AUTOSAR XML (schema 00047)
standard types defined: boolean, uint16, uint32, uint8
package /Application/AdaptiveApplicationSwComponentTypes
  adaptive application sw component type DiagnosticManagerDeamon
    require port DiagComApiDeamonPort: required-interface=DiagComApi
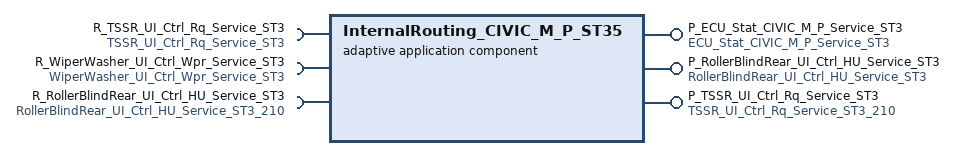
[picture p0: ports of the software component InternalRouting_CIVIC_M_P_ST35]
  adaptive application sw component type InternalRouting_CIVIC_M_P_ST35
    provide port P_ECU_Stat_CIVIC_M_P_Service_ST3: provided-interface=ECU_Stat_CIVIC_M_P_Service_ST3
    require port R_TSSR_UI_Ctrl_Rq_Service_ST3: required-interface=TSSR_UI_Ctrl_Rq_Service_ST3
    require port R_WiperWasher_UI_Ctrl_Wpr_Service_ST3: required-interface=WiperWasher_UI_Ctrl_Wpr_Service_ST3
    provide port P_RollerBlindRear_UI_Ctrl_HU_Service_ST3: provided-interface=RollerBlindRear_UI_Ctrl_HU_Service_ST3
    require port R_RollerBlindRear_UI_Ctrl_HU_Service_ST3: required-interface=RollerBlindRear_UI_Ctrl_HU_Service_ST3_210
    provide port P_TSSR_UI_Ctrl_Rq_Service_ST3: provided-interface=TSSR_UI_Ctrl_Rq_Service_ST3_210
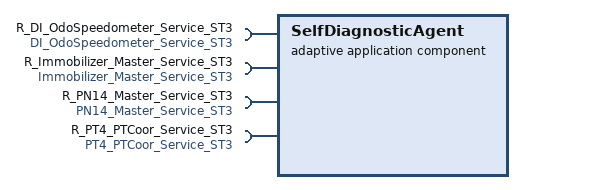
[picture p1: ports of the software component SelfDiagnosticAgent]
  adaptive application sw component type SelfDiagnosticAgent
    4 x require port:
      R_DI_OdoSpeedometer_Service_ST3: required-interface=DI_OdoSpeedometer_Service_ST3
      R_Immobilizer_Master_Service_ST3: required-interface=Immobilizer_Master_Service_ST3
      R_PN14_Master_Service_ST3: required-interface=PN14_Master_Service_ST3
      R_PT4_PTCoor_Service_ST3: required-interface=PT4_PTCoor_Service_ST3
  adaptive application sw component type SsaDiag_swc
    provide port amsr_DiagComApi: provided-interface=DiagComApi
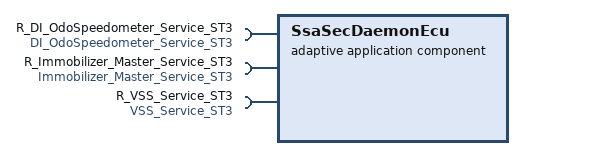
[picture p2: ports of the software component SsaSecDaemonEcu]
  adaptive application sw component type SsaSecDaemonEcu
    require port R_DI_OdoSpeedometer_Service_ST3: required-interface=DI_OdoSpeedometer_Service_ST3
    require port R_Immobilizer_Master_Service_ST3: required-interface=Immobilizer_Master_Service_ST3
    require port R_VSS_Service_ST3: required-interface=VSS_Service_ST3
package /Application/Executables
  5 x executable, all with category=APPLICATION_LEVEL, build-type=BUILD-TYPE-DEBUG, version=1.00.00.0000:
    DiagnosticManagerDeamon_Executable
      root sw component prototype DiagnosticManagerDeamon_ExecutableRootSwc: application-type=DiagnosticManagerDeamon
    InternalRouting_CIVIC_M_P_ST35_Executable
      root sw component prototype InternalRouting_CIVIC_M_P_ST35_ExecutableRootSwc: application-type=InternalRouting_CIVIC_M_P_ST35
    SelfDiagnosticAgent_Executable
      root sw component prototype SelfDiagnosticAgent_ExecutableRootSwc: application-type=SelfDiagnosticAgent
    amsr_ssadiag
      root sw component prototype amsr_ssadiagRootSwc: application-type=SsaDiag_swc
    amsr_ssasecd
      root sw component prototype amsr_ssasecdRootSwc: application-type=SsaSecDaemonEcu
package /ApplicationDeployment/ProcessDesigns
  5 x process design:
    DiagnosticManagerDeamonDesign: executable=DiagnosticManagerDeamon_Executable
    InternalRouting_CIVIC_M_P_ST35_ProcessDesign: executable=InternalRouting_CIVIC_M_P_ST35_Executable
    SelfDiagnosticAgent_ProcessDesign: executable=SelfDiagnosticAgent_Executable
    amsr_ssadiagdDesign: executable=amsr_ssadiag
    amsr_ssasecdDesign: executable=amsr_ssasecd
package /ApplicationDeployment/Processes
  5 x process:
    DiagnosticManagerDeamon: design=DiagnosticManagerDeamonDesign, executable=DiagnosticManagerDeamon_Executable, state-dependent-startup-config{function-group-state=MachineState.Running, startup-config=STARTUP_CONFIG_DEFAULT}
    InternalRouting_CIVIC_M_P_ST35_Process: design=InternalRouting_CIVIC_M_P_ST35_ProcessDesign, executable=InternalRouting_CIVIC_M_P_ST35_Executable, state-dependent-startup-config{function-group-state=MachineState.Running, startup-config=STARTUP_CONFIG_DEFAULT}
      process state machine ProcessStateMachine_InternalRouting_CIVIC_M_P_ST35: type=MachineStates
    SelfDiagnosticAgent_Process: design=SelfDiagnosticAgent_ProcessDesign, executable=SelfDiagnosticAgent_Executable, state-dependent-startup-config{function-group-state=MachineState.Running, startup-config=STARTUP_CONFIG_DEFAULT}
      process state machine ProcessStateMachine_SelfDiagnosticAgent: type=MachineStates
    amsr_ssadiagd: design=amsr_ssadiagdDesign, executable=amsr_ssadiag, state-dependent-startup-config{function-group-state=MachineState.Running, startup-config=SsaDiag_startup_config}
      process state machine ProcessStateMachine_amsr_ssadiagd: type=MachineStates
    amsr_ssasecd: design=amsr_ssasecdDesign, executable=amsr_ssasecd, state-dependent-startup-config{function-group-state=MachineState.Running, startup-config=startup_config}
      process state machine ProcessStateMachine_amsr_ssasecd: type=MachineStates
package /Communication/PDUs
  pdu DI_OdoSpeedometer_ST3: length=8, minimum-delay=0.1, unused-bit-pattern=255  # DriverInformation Odometer and speedometer
    signal Odo_ST3: start 24, 24 bit, little-endian, data-type-policy=OVERRIDE, i-signal-type=PRIMITIVE, base-type=uint32, invalid-value=16777215, compu {phys=raw*0.1 for raw 0..9999999, 16777214=I_C24_KM_0_999999K9_0K1_INVLD_SNA_INVLD (INVLD) (Invalid), 16777215=I_C24_KM_0_999999K9_0K1_INVLD_SNA_SNA (SNA) (SNA value from data type); unit km}, range phys 0..1677721.5, raw 0..16777215 "24_km_0-999999,9_0,1_Invld_SNA", to CIVIC_M_P_STAR_35_ExecutionContext  # Odometer (for everyone)
    mapping CRC_DI_Odo_Pr5_ST3: transfer-property=PENDING
    mapping DI_Odo_Pr5_ST3_e68xmtlkywxgxsdwekdjjhw3t: i-signal-group=DI_Odo_Pr5_ST3_e68xmtlkywxgxsdwekdjjhw3t, transfer-property=TRIGGERED-ON-CHANGE
    mapping SQC_DI_Odo_Pr5_ST3: transfer-property=PENDING
    mapping VehSpd_Disp_ST3: transfer-property=PENDING
  pdu ECU_Stat_CIVIC_M_P_ST3: length=8, unused-bit-pattern=0  # ECU state
    signal ECU_Id_CIVIC_M_P_ST3: start 0, 12 bit, little-endian, data-type-policy=OVERRIDE, i-signal-type=PRIMITIVE, base-type=uint16, invalid-value=4095, compu {phys=raw for raw 0..4094, 4095=I_C12_0_4094_1_SNA_SNA (SNA) (SNA value from data type)}, range phys 0..4095, raw 0..4095 "12_0-4094_1_SNA", transfer-property=PENDING  # ECU identifier
    signal WakeupRsn_CIVIC_M_P_ST3: start 20, 10 bit, little-endian, data-type-policy=OVERRIDE, i-signal-type=PRIMITIVE, base-type=uint16, invalid-value=1023, compu {0=I_C10_WAKEUPRSN_ST3_NETWORK (NETWORK) (Wakeup by network), 1=I_C10_WAKEUPRSN_ST3_NW_MAIN (NW_MAIN) (Wakeup by MAIN Ethernet), 11=I_C10_WAKEUPRSN_ST3_NW_HEADUNIT1 (NW_HEADUNIT1) (Wakeup by HEADUNIT1 CAN), 12=I_C10_WAKEUPRSN_ST3_NW_HEADUNIT2 (NW_HEADUNIT2) (Wakeup by HEADUNIT2 CAN), 13=I_C10_WAKEUPRSN_ST3_NW_PERIPHERY (NW_PERIPHERY) (Wakeup by PERIPHERY CAN), 14=I_C10_WAKEUPRSN_ST3_NW_BODY1 (NW_BODY1) (Wakeup by BODY1 CAN), 15=I_C10_WAKEUPRSN_ST3_NW_CHASSIS (NW_CHASSIS) (Wakeup by CHASSIS FlexRay), 16=I_C10_WAKEUPRSN_ST3_NW_RADAR_R (NW_RADAR_R) (Wakeup by RADAR_R CAN), 17=I_C10_WAKEUPRSN_ST3_NW_RADAR_F (NW_RADAR_F) (Wakeup by RADAR_F CAN), 18=I_C10_WAKEUPRSN_ST3_NW_OBD_PTI (NW_OBD_PTI) (Wakeup by OBD_PTI CAN), 19=I_C10_WAKEUPRSN_ST3_NW_STEERING_WHEEL (NW_STEERING_WHEEL) (Wakeup by STEERING_WHEEL CAN), 20=I_C10_WAKEUPRSN_ST3_NW_CPC (NW_CPC) (Wakeup by CPC CAN), 21=I_C10_WAKEUPRSN_ST3_NW_ECM (NW_ECM) (Wakeup by ECM CAN), 22=I_C10_WAKEUPRSN_ST3_NW_ENERGY (NW_ENERGY) (Wakeup by ENERGY CAN), 23=I_C10_WAKEUPRSN_ST3_NW_INV (NW_INV) (Wakeup by INV CAN), 24=I_C10_WAKEUPRSN_ST3_NW_TCM (NW_TCM) (Wakeup by TCM CAN), 25=I_C10_WAKEUPRSN_ST3_NW_AEPU (NW_AEPU) (Wakeup by AEPU CAN), 26=I_C10_WAKEUPRSN_ST3_NW_BODY2 (NW_BODY2) (Wakeup by BODY2 CAN), 27=I_C10_WAKEUPRSN_ST3_NW_BODY3 (NW_BODY3) (Wakeup by BODY3 CAN), 28=I_C10_WAKEUPRSN_ST3_NW_CAL_COC (NW_CAL_COC) (Wakeup by CAL_COC CAN), 29=I_C10_WAKEUPRSN_ST3_NW_CAL_DL (NW_CAL_DL) (Wakeup by CAL_DL CAN), 30=I_C10_WAKEUPRSN_ST3_NW_CAL_DR (NW_CAL_DR) (Wakeup by CAL_DR CAN), 31=I_C10_WAKEUPRSN_ST3_NW_ECM_PERIPHERY1 (NW_ECM_PERIPHERY1) (Wakeup by ECM_PERIPHERY1 CAN), 32=I_C10_WAKEUPRSN_ST3_NW_ECM_PERIPHERY2 (NW_ECM_PERIPHERY2) (Wakeup by ECM_PERIPHERY2 CAN), 33=I_C10_WAKEUPRSN_ST3_NW_ENGINE_PT3 (NW_ENGINE_PT3) (Wakeup by ENGINE_PT3 CAN), 34=I_C10_WAKEUPRSN_ST3_NW_HAD_BACKUP (NW_HAD_BACKUP) (Wakeup by HAD_BACKUP CAN), 35=I_C10_WAKEUPRSN_ST3_NW_HYBRID_PT3 (NW_HYBRID_PT3) (Wakeup by HYBRID_PT3 CAN), 36=I_C10_WAKEUPRSN_ST3_NW_LSM_F (NW_LSM_F) (Wakeup by LSM_F CAN), 37=I_C10_WAKEUPRSN_ST3_NW_POWERTRAIN_PT3 (NW_POWERTRAIN_PT3) (Wakeup by POWERTRAIN_PT3 CAN), 38=I_C10_WAKEUPRSN_ST3_NW_PT_SENSOR_PT3 (NW_PT_SENSOR_PT3) (Wakeup by PT_SENSOR_PT3 CAN), 39=I_C10_WAKEUPRSN_ST3_NW_RVC_HSVL (NW_RVC_HSVL) (Wakeup by RVC_HSVL CAN), 40=I_C10_WAKEUPRSN_ST3_NW_SPV (NW_SPV) (Wakeup by SPV CAN), 41=I_C10_WAKEUPRSN_ST3_NW_SUSPENSION_F (NW_SUSPENSION_F) (Wakeup by SUSPENSION_F CAN), 42=I_C10_WAKEUPRSN_ST3_NW_SUSPENSION_R (NW_SUSPENSION_R) (Wakeup by SUSPENSION_R CAN), 43=I_C10_WAKEUPRSN_ST3_NW_EIS_BASE_GW (NW_EIS_BASE_GW) (Wakeup by EIS_BASE_GW CAN), 44=I_C10_WAKEUPRSN_ST3_NW_EIS_GW_BASE (NW_EIS_GW_BASE) (Wakeup by EIS_GW_BASE CAN), 45=I_C10_WAKEUPRSN_ST3_NW_AUXILIARY1 (NW_AUXILIARY1) (Wakeup by AUXILIARY1 CAN), 46=I_C10_WAKEUPRSN_ST3_NW_AUXILIARY2 (NW_AUXILIARY2) (Wakeup by AUXILIARY2 CAN), 47=I_C10_WAKEUPRSN_ST3_NW_DRIVE_UNIT (NW_DRIVE_UNIT) (Wakeup by DRIVE_UNIT CAN), 48=I_C10_WAKEUPRSN_ST3_NW_INLET (NW_INLET) (Wakeup by INLET CAN), 49=I_C10_WAKEUPRSN_ST3_NW_BODY4 (NW_BODY4) (Wakeup by BODY4 CAN), 115=I_C10_WAKEUPRSN_ST3_LIN_HVAC_F (LIN_HVAC_F) (Wakeup by LIN-Slave HVAC_F), 116=I_C10_WAKEUPRSN_ST3_LIN_HVAC_R (LIN_HVAC_R) (Wakeup by LIN-Slave HVAC_R), 117=I_C10_WAKEUPRSN_ST3_LIN_VCS (LIN_VCS) (Wakeup by LIN-Slave VCS), 118=I_C10_WAKEUPRSN_ST3_LIN_WPRA (LIN_WPRA) (Wakeup by LIN-Slave WPRA), 119=I_C10_WAKEUPRSN_ST3_LIN_IHTM_RC (LIN_IHTM_RC) (Wakeup by LIN-Slave IHTM_RC), 120=I_C10_WAKEUPRSN_ST3_LIN_PTC48_R (LIN_PTC48_R) (Wakeup by LIN-Slave PTC48_R), 121=I_C10_WAKEUPRSN_ST3_LIN_AQS (LIN_AQS) (Wakeup by LIN-Slave AQS), 122=I_C10_WAKEUPRSN_ST3_LIN_ECP2_1 (LIN_ECP2_1) (Wakeup by LIN-Slave ECP2_1), 123=I_C10_WAKEUPRSN_ST3_LIN_EXV1 (LIN_EXV1) (Wakeup by LIN-Slave EXV1), 124=I_C10_WAKEUPRSN_ST3_LIN_IHTM (LIN_IHTM) (Wakeup by LIN-Slave IHTM), 125=I_C10_WAKEUPRSN_ST3_LIN_EAC (LIN_EAC) (Wakeup by LIN-Slave EAC), 126=I_C10_WAKEUPRSN_ST3_LIN_EAC48 (LIN_EAC48) (Wakeup by LIN-Slave EAC48), 127=I_C10_WAKEUPRSN_ST3_LIN_PTC_HV (LIN_PTC_HV) (Wakeup by LIN-Slave PTC_HV), 128=I_C10_WAKEUPRSN_ST3_TERM_15 (TERM_15) (Wakeup by discrete terminal 15 signal), 130=I_C10_WAKEUPRSN_ST3_TERM_54 (TERM_54) (Wakeup by terminal 54 active), 131=I_C10_WAKEUPRSN_ST3_LIN_HFA (LIN_HFA) (Wakeup by LIN-Slave Hands Free Access), 132=I_C10_WAKEUPRSN_ST3_LIN_IBS (LIN_IBS) (Wakeup by LIN-Slave Battery sensor), 133=I_C10_WAKEUPRSN_ST3_LIN_DOOR_HANDLE (LIN_DOOR_HANDLE) (Wakeup by LIN-Slave Door Handle), 134=I_C10_WAKEUPRSN_ST3_LIN_LISB48 (LIN_LISB48) (Wakeup by LIN-Slave LISB48), 135=I_C10_WAKEUPRSN_ST3_CMN_ECU_RST_POR (CMN_ECU_RST_POR) (Wakeup by ECU Power On Reset, Common Reason), 136=I_C10_WAKEUPRSN_ST3_CMN_ECU_RST_DIAG (CMN_ECU_RST_DIAG) (Wakeup by ECU Diagnostic Reset, Common Reason), 137=I_C10_WAKEUPRSN_ST3_CMN_ECU_RST_TEST (CMN_ECU_RST_TEST) (Wakeup by ECU Test Reset, Common Reason), 138=I_C10_WAKEUPRSN_ST3_CMN_ECU_RST_ERR (CMN_ECU_RST_ERR) (Wakeup by ECU Error Reset, Common Reason), 139=I_C10_WAKEUPRSN_ST3_CMN_ETH_WAKEUPLINE (CMN_ETH_WAKEUPLINE) (Wakeup by Ethernet Wakeup-Line, Common Reason), 140=I_C10_WAKEUPRSN_ST3_CMN_AFTERRUN (CMN_AFTERRUN) (Wakeup by afterrun, Common Reason), 141=I_C10_WAKEUPRSN_ST3_CRASH (CRASH) (Wakeup by crash signal), 142=I_C10_WAKEUPRSN_ST3_LIN_VCI (LIN_VCI) (Wakeup by LIN-Slave VCI), 143=I_C10_WAKEUPRSN_ST3_LIN_CIS (LIN_CIS) (Wakeup by LIN-Slave CIS), 181=I_C10_WAKEUPRSN_ST3_EASY_ENTRY_ACTV (EASY_ENTRY_ACTV) (Wakeup by Easy Entry active), 183=I_C10_WAKEUPRSN_ST3_ERR_SEAT_HTVN (ERR_SEAT_HTVN) (Wakeup by error seat heating/ventilation), 184=I_C10_WAKEUPRSN_ST3_ERR_SEAT_CHM (ERR_SEAT_CHM) (Wakeup by error console heating), 199=I_C10_WAKEUPRSN_ST3_VEHSL_EVENT (VEHSL_EVENT) (Wakeup by Vehicle State Living signal update), 200=I_C10_WAKEUPRSN_ST3_RLS (RLS) (Wakeup by rotary light switch), 201=I_C10_WAKEUPRSN_ST3_EF_KEY (EF_KEY) (Wakeup by emergency flasher key), 202=I_C10_WAKEUPRSN_ST3_RHU_FT (RHU_FT) (Wakeup by residual heat utilization front), 203=I_C10_WAKEUPRSN_ST3_RHU_R (RHU_R) (Wakeup by residual heat utilization rear), 204=I_C10_WAKEUPRSN_ST3_ICH_RQ (ICH_RQ) (Wakeup by idependent car heater request), 205=I_C10_WAKEUPRSN_ST3_VPRZR_VN (VPRZR_VN) (Wakeup by Vaporizer ventilation), 206=I_C10_WAKEUPRSN_ST3_PRECON (PRECON) (Wakeup by PreConditioning), 207=I_C10_WAKEUPRSN_ST3_SOL_VN (SOL_VN) (Wakeup by Solar Ventilation), 208=I_C10_WAKEUPRSN_ST3_EXTLGT_ACTV (EXTLGT_ACTV) (Wakeup by exterior lighting active), 209=I_C10_WAKEUPRSN_ST3_INTLGT_ACTV (INTLGT_ACTV) (Wakeup by interior lighting active), 210=I_C10_WAKEUPRSN_ST3_TSSR_ACTV (TSSR_ACTV) (Wakeup by TSSR active), 211=I_C10_WAKEUPRSN_ST3_SEAT_HT_F_ACTV (SEAT_HT_F_ACTV) (Wakeup by seat heating front active), 212=I_C10_WAKEUPRSN_ST3_SEAT_HT_R_ACTV (SEAT_HT_R_ACTV) (Wakeup by seat heating rear active), 213=I_C10_WAKEUPRSN_ST3_SEAT_VN_F_ACTV (SEAT_VN_F_ACTV) (Wakeup by seat ventilation front active), 214=I_C10_WAKEUPRSN_ST3_SEAT_VN_R_ACTV (SEAT_VN_R_ACTV) (Wakeup by seat ventilation rear active), 215=I_C10_WAKEUPRSN_ST3_EHS_3S (EHS_3S) (Wakeup by 3S engine hood switch (Pawl)), 216=I_C10_WAKEUPRSN_ST3_T58D_POTI (T58D_POTI) (Wakeup by terminal 58d potentiometer), 217=I_C10_WAKEUPRSN_ST3_DRB (DRB) (Wakeup by Double Roller Blind), 218=I_C10_WAKEUPRSN_ST3_BKRST_UNLK_RM (BKRST_UNLK_RM) (Wakeup by Backrest Unlock rear Middle), 219=I_C10_WAKEUPRSN_ST3_DL_SW2_PSD (DL_SW2_PSD) (Wakeup by Deck Lid Switch Pressed 2), 220=I_C10_WAKEUPRSN_ST3_DL_SW (DL_SW) (Wakeup by deck lid switch pressed), 221=I_C10_WAKEUPRSN_ST3_BGC_SW (BGC_SW) (Wakeup by switch inside baggage compartment pressed), 222=I_C10_WAKEUPRSN_ST3_BKRST_RL_LK_UNLK (BKRST_RL_LK_UNLK) (Wakeup by back rest rear left locked or unlocked), 223=I_C10_WAKEUPRSN_ST3_BKRST_RR_LK_UNLK (BKRST_RR_LK_UNLK) (Wakeup by back rest rear right locked or unlocked), 224=I_C10_WAKEUPRSN_ST3_DL_CLS_LK_SW (DL_CLS_LK_SW) (Wakeup by deck lid switch close/lock close pressed), 225=I_C10_WAKEUPRSN_ST3_DL_RLTCH (DL_RLTCH) (Wakeup by deck lid rotary latch pressed), 226=I_C10_WAKEUPRSN_ST3_BKRST_3L_LK_UNLK (BKRST_3L_LK_UNLK) (Wakeup by back rest 3rd row left locked or unlocked), 227=I_C10_WAKEUPRSN_ST3_BKRST_3R_LK_UNLK (BKRST_3R_LK_UNLK) (Wakeup by back rest 3rd row right locked or unlocked), 228=I_C10_WAKEUPRSN_ST3_GAS_DR_SW (GAS_DR_SW) (Wakeup by gas door switch), 229=I_C10_WAKEUPRSN_ST3_AILCF (AILCF) (Wakeup by AILCF), 230=I_C10_WAKEUPRSN_ST3_AILCC (AILCC) (Wakeup by AILCC), 256=I_C10_WAKEUPRSN_ST3_TRLR_ELEC_ACT (TRLR_ELEC_ACT) (Wakeup by electrical trailer hitch activation), 257=I_C10_WAKEUPRSN_ST3_TRLR_DET (TRLR_DET) (Wakeup by trailer detected), 258=I_C10_WAKEUPRSN_ST3_DL_LK (DL_LK) (Wakeup by delayed locking), 259=I_C10_WAKEUPRSN_ST3_START_SW_PSD (START_SW_PSD) (Wakeup by start switch pressed), 260=I_C10_WAKEUPRSN_ST3_RADIO_DATA (RADIO_DATA) (Wakeup by radio data), 261=I_C10_WAKEUPRSN_ST3_RLTCH_DR (RLTCH_DR) (Wakeup by rotational latch door), 263=I_C10_WAKEUPRSN_ST3_PKBRKSW (PKBRKSW) (Wakeup by Parking switch pressed), 264=I_C10_WAKEUPRSN_ST3_KEYLESS_GO (KEYLESS_GO) (Wakeup by Keyless Go/Start (Core 1/0)), 265=I_C10_WAKEUPRSN_ST3_PNM12 (PNM12) (Wakeup by Power network management 12V), 266=I_C10_WAKEUPRSN_ST3_PNM48 (PNM48) (Wakeup by Power network management 48V), 267=I_C10_WAKEUPRSN_ST3_BAT48_LOWCHARGE (BAT48_LOWCHARGE) (Wakeup by 48V battery due to low charge), 270=I_C10_WAKEUPRSN_ST3_PN14_IODM (PN14_IODM) (Wakeup by IOD Measurement), 271=I_C10_WAKEUPRSN_ST3_PN14_REMSRV_STAT (PN14_REMSRV_STAT) (Wakeup by Change of Remote Service Status), 272=I_C10_WAKEUPRSN_ST3_PN14_DDP (PN14_DDP) (Wakeup by Deep Discharge Protection), 273=I_C10_WAKEUPRSN_ST3_PN14_LOWCHARGE (PN14_LOWCHARGE) (Wakeup by low charge of the battery), 274=I_C10_WAKEUPRSN_ST3_PN14_REMODHV12V (PN14_REMODHV12V) (Wakeup by reload mode HV 12V), 275=I_C10_WAKEUPRSN_ST3_PN14_DLM (PN14_DLM) (Wakeup by Powernet CutOff (Dynamic Load Management)), 276=I_C10_WAKEUPRSN_ST3_SDC_PN2_LOWCHARGE (SDC_PN2_LOWCHARGE) (Wakeup by low charge of the battery in SDC_PNM2), 277=I_C10_WAKEUPRSN_ST3_SDC_PN2_REMODHV12V (SDC_PN2_REMODHV12V) (Wakeup by reload mode HV 12 in SDC_PNM2), 280=I_C10_WAKEUPRSN_ST3_DATA_EXCHG (DATA_EXCHG) (Wakeup by data exchange with vehicle functions), 281=I_C10_WAKEUPRSN_ST3_INTERNET_CON (INTERNET_CON) (Wakeup by internet connection), 282=I_C10_WAKEUPRSN_ST3_CMN_USER_DATA (CMN_USER_DATA) (Wakeup by user data, Common Reason), 290=I_C10_WAKEUPRSN_ST3_CMN_SERV_LOCAL (CMN_SERV_LOCAL) (Wakeup by local activated service, Common Reason), 291=I_C10_WAKEUPRSN_ST3_CMN_SERV_REM (CMN_SERV_REM) (Wakeup by remote activated service, Common Reason), 292=I_C10_WAKEUPRSN_ST3_VEH_REAR_LOWERING (VEH_REAR_LOWERING) (Wakeup by vehicle rear lowering), 300=I_C10_WAKEUPRSN_ST3_CMN_BTN_PSD (CMN_BTN_PSD) (Wakeup by button pressed, Common Reason), 301=I_C10_WAKEUPRSN_ST3_FLAP_PSD (FLAP_PSD) (Wakeup by flap pressed), 302=I_C10_WAKEUPRSN_ST3_CHADEMO (CHADEMO) (Wakeup by CHADEMO charging system), 303=I_C10_WAKEUPRSN_ST3_GBT (GBT) (Wakeup by GBT charging system), 304=I_C10_WAKEUPRSN_ST3_CMN_PROXIMITY (CMN_PROXIMITY) (Wakeup by proximity, Common Reason), 305=I_C10_WAKEUPRSN_ST3_CTRL_PILOT (CTRL_PILOT) (Wakeup by control pilot), 306=I_C10_WAKEUPRSN_ST3_CMN_HV_DET (CMN_HV_DET) (Wakeup by HiVolt detection, Common Reason), 307=I_C10_WAKEUPRSN_ST3_CMN_CHRG_TMR (CMN_CHRG_TMR) (Wakeup by charging timer, Common Reason), 308=I_C10_WAKEUPRSN_ST3_TRCT_BAT_OP_STRATEGY (TRCT_BAT_OP_STRATEGY) (Wakeup by traction battery operating strategy), 309=I_C10_WAKEUPRSN_ST3_VTA (VTA) (Wakeup by VTA alarm), 310=I_C10_WAKEUPRSN_ST3_PDD (PDD) (Wakeup by PDD collision detected), 311=I_C10_WAKEUPRSN_ST3_UNEQUAL_STRING_VOLT (UNEQUAL_STRING_VOLT) (Wakeup by unequal string voltages), 312=I_C10_WAKEUPRSN_ST3_MUTE_ACTV (MUTE_ACTV) (Wakeup by mute activated), 313=I_C10_WAKEUPRSN_ST3_VIDEO_RQ (VIDEO_RQ) (Wakeup by video in request), 314=I_C10_WAKEUPRSN_ST3_ALARM_ACTV (ALARM_ACTV) (Wakeup by alarm activation), 315=I_C10_WAKEUPRSN_ST3_RECIRC_AIR_RQ (RECIRC_AIR_RQ) (Wakeup by FLA/NFS recirc air request), 316=I_C10_WAKEUPRSN_ST3_TPM_SYNC (TPM_SYNC) (Wakeup by TPM synchronize BackEndServer), 320=I_C10_WAKEUPRSN_ST3_DI_DISP_RQ (DI_DISP_RQ) (Wakeup by DI display request), 321=I_C10_WAKEUPRSN_ST3_DI_IND_RQ (DI_IND_RQ) (Wakeup by DI indicator request), 322=I_C10_WAKEUPRSN_ST3_HUD_RQ (HUD_RQ) (Wakeup by HUD request), 325=I_C10_WAKEUPRSN_ST3_MSG_DISP_RQ (MSG_DISP_RQ) (Wakeup by message display request), 326=I_C10_WAKEUPRSN_ST3_ROOF_LMP_ON_RQ (ROOF_LMP_ON_RQ) (Wakeup by rooflamps on request), 327=I_C10_WAKEUPRSN_ST3_IL_ON_RQ (IL_ON_RQ) (Wakeup by interior light activated from special vehicle), 328=I_C10_WAKEUPRSN_ST3_SPS_APPL (SPS_APPL) (Wakeup by special vehicle application), 330=I_C10_WAKEUPRSN_ST3_PWC_WRAPPER (PWC_WRAPPER) (Wakeup by PWC Wrapper), 331=I_C10_WAKEUPRSN_ST3_PW_SW (PW_SW) (Wakeup by power window switch), 332=I_C10_WAKEUPRSN_ST3_CLKS_SW (CLKS_SW) (Wakeup by centrol locking system switch), 333=I_C10_WAKEUPRSN_ST3_SEAT_SW (SEAT_SW) (Wakeup by seat switch), 334=I_C10_WAKEUPRSN_ST3_DL_REM_SW (DL_REM_SW) (Wakeup by deck lid remote switch), 335=I_C10_WAKEUPRSN_ST3_TANK_UNLK_SW (TANK_UNLK_SW) (Wakeup by tank unlock switch), 336=I_C10_WAKEUPRSN_ST3_SLTCH_DR (SLTCH_DR) (Wakeup by secondary latch), 337=I_C10_WAKEUPRSN_ST3_INSRLVR_SW (INSRLVR_SW) (Wakeup by inside release lever switch), 338=I_C10_WAKEUPRSN_ST3_OUTSRLVR_SW (OUTSRLVR_SW) (Wakeup by outside release lever switch), 339=I_C10_WAKEUPRSN_ST3_TRL_HTCH_SW (TRL_HTCH_SW) (Wakeup by trailer hitch switch), 340=I_C10_WAKEUPRSN_ST3_TSSR_R_RB_SW (TSSR_R_RB_SW) (Wakeup by TSSR switch), 341=I_C10_WAKEUPRSN_ST3_CSL_SW (CSL_SW) (Wakeup by child security switch), 342=I_C10_WAKEUPRSN_ST3_GEAR_SW (GEAR_SW) (Wakeup by gear switch), 343=I_C10_WAKEUPRSN_ST3_AD_SW (AD_SW) (Wakeup by automated door switch), 344=I_C10_WAKEUPRSN_ST3_T2R_SW (T2R_SW) (Wakeup by automated door Tip2Run), 345=I_C10_WAKEUPRSN_ST3_HV_INTERLOCK_ERR (HV_INTERLOCK_ERR) (Wakeup by interlock error), 346=I_C10_WAKEUPRSN_ST3_NFC (NFC) (Wakeup by NFC), 347=I_C10_WAKEUPRSN_ST3_POLLING (POLLING) (Wakeup by Polling (COD belonging to the car was detected)), 348=I_C10_WAKEUPRSN_ST3_TSL_P_PSD (TSL_P_PSD) (Wakeup by Transmission Selector Lever P button pressed), 349=I_C10_WAKEUPRSN_ST3_STWHL_LVR_PSD (STWHL_LVR_PSD) (Wakeup by Steering Wheel Lever pressed), 350=I_C10_WAKEUPRSN_ST3_BAT14_DDP (BAT14_DDP) (Wakeup by Deep discharge protection), 351=I_C10_WAKEUPRSN_ST3_BAT14_LOWCHARGE (BAT14_LOWCHARGE) (Wakeup by low charge of the 12V battery), 352=I_C10_WAKEUPRSN_ST3_BAT14_CHARGECURR (BAT14_CHARGECURR) (Wakeup by charge Current detection), 353=I_C10_WAKEUPRSN_ST3_BAT14_IODM (BAT14_IODM) (Wakeup by IOD Measurement), 354=I_C10_WAKEUPRSN_ST3_BAT14_IODAVG (BAT14_IODAVG) (Wakeup by Average IOD Measurement), 355=I_C10_WAKEUPRSN_ST3_BMS_TMR (BMS_TMR) (Wakeup by BMS timer), 356=I_C10_WAKEUPRSN_ST3_CPD (CPD) (Wakeup by child presence detection), 400=I_C10_WAKEUPRSN_ST3_FOTA_TMR (FOTA_TMR) (Wakeup by FOTA Timer), 1020=I_C10_WAKEUPRSN_ST3_RESERVE_3 (RESERVE_3) (Wakeup by Reserve 3), 1021=I_C10_WAKEUPRSN_ST3_RESERVE_2 (RESERVE_2) (Wakeup by Reserve 2), 1022=I_C10_WAKEUPRSN_ST3_RESERVE_1 (RESERVE_1) (Wakeup by Reserve 1), 1023=I_C10_WAKEUPRSN_ST3_SNA (SNA) (SNA value from data type)} "1 - 99: Networks,e.g. MAIN Wakeup by MAIN - CHASSIS Wakeup by CHASSIS -ENGINE Wakeup by ENGINE | What about LIN? 100 - 1022: ECU-specific wakeup reasons, generically so that the reasons can be used by all ECUs", range raw 0..1023 "10_WakeupRsn_ST3", transfer-property=PENDING  # Wakeup reason
    signal Awake_Diag_Actv_CIVIC_M_P_ST3: start 30, 1 bit, little-endian, data-type-policy=OVERRIDE, i-signal-type=PRIMITIVE, base-type=boolean, transfer-property=PENDING  # Stay awake for diagnostics active
    signal Awake_NwStart_CIVIC_M_P_ST3: start 31, 1 bit, little-endian, data-type-policy=OVERRIDE, i-signal-type=PRIMITIVE, base-type=boolean, transfer-property=PENDING  # Stay awake for network startup
    signal Awake_HAD_Actv_CIVIC_M_P_ST3: start 32, 1 bit, little-endian, data-type-policy=OVERRIDE, i-signal-type=PRIMITIVE, base-type=boolean, transfer-property=PENDING  # Stay awake for HAD active
    signal Awake_Ignition_On_CIVIC_M_P_ST3: start 33, 1 bit, little-endian, data-type-policy=OVERRIDE, i-signal-type=PRIMITIVE, base-type=boolean, transfer-property=PENDING  # Stay awake for ignition on from CIVIC_M_P
    mapping NwId_Rsrv_ST3: transfer-property=PENDING
    mapping SignalIPDUAssignment14738: i-signal-group=ECU_Stat_CIVIC_M_P_ST3
  pdu Ign_Stat_ST3: length=4, minimum-delay=0.02, unused-bit-pattern=255  # Ignition state
    signal ISw_Stat_ST3: start 24, 3 bit, little-endian, data-type-policy=OVERRIDE, i-signal-type=PRIMITIVE, base-type=uint8, invalid-value=7, compu {0=I_C03_ISW_STAT_IGN_LOCK (IGN_LOCK) (Ignition lock (0)), 1=I_C03_ISW_STAT_IGN_OFF (IGN_OFF) (Ignition off (15c)), 2=I_C03_ISW_STAT_IGN_ACC (IGN_ACC) (Ignition accessory (15r)), 4=I_C03_ISW_STAT_IGN_ON (IGN_ON) (Ignition on (15)), 5=I_C03_ISW_STAT_IGN_START (IGN_START) (Ignition start (50)), 7=I_C03_ISW_STAT_SNA (SNA) (SNA value from data type)}, range raw 0..7 "03_ISw_Stat", to CIVIC_M_P_STAR_35_ExecutionContext  # Ignition switch state
    mapping CRC_Ign_Stat_Pr5_ST3: transfer-property=PENDING
    mapping Ign_Stat_Pr5_ST3_csgs1dv6drms80o1i9p49677w: i-signal-group=Ign_Stat_Pr5_ST3_csgs1dv6drms80o1i9p49677w, transfer-property=TRIGGERED-ON-CHANGE
    mapping KG_StartSw_Psd_ST3: transfer-property=PENDING
    mapping SQC_Ign_Stat_Pr5_ST3: transfer-property=PENDING
    mapping Veh_Op_Mode_ST3: transfer-property=PENDING
  pdu PN14_Master_Stat1_ST3: length=8, unused-bit-pattern=255  # Powernetwork 12V master state
    signal PN14_TransMd_Stat_ST3: start 0, 2 bit, little-endian, data-type-policy=OVERRIDE, i-signal-type=PRIMITIVE, base-type=uint8, invalid-value=3, compu {0=I_C02_TRANSMD_STAT_OFF (OFF) (Transport mode permanently off), 1=I_C02_TRANSMD_STAT_TEMP_OFF (TEMP_OFF) (Transport mode temporarily off), 2=I_C02_TRANSMD_STAT_ACTV (ACTV) (Transport mode active), 3=I_C02_TRANSMD_STAT_SNA (SNA) (SNA value from data type)}, range raw 0..3 "02_TransMd_Stat", transfer-property=PENDING, to CIVIC_M_P_STAR_35_ExecutionContext  # Powernet transport mode status
    signal PN14_ProdMd_Stat_ST3: start 5, 3 bit, little-endian, data-type-policy=OVERRIDE, i-signal-type=PRIMITIVE, base-type=uint8, invalid-value=7, compu {0=I_C03_PN14_PRODMD_STAT_ST3_OFF (OFF) (Productionmode off), 1=I_C03_PN14_PRODMD_STAT_ST3_ON (ON) (Productionmode active), 2=I_C03_PN14_PRODMD_STAT_ST3_SF01 (SF01) (Productionmode Special Funcion 1), 3=I_C03_PN14_PRODMD_STAT_ST3_SF02 (SF02) (Productionmode Special Funcion 2), 4=I_C03_PN14_PRODMD_STAT_ST3_SF03 (SF03) (Productionmode Special Funcion 3), 7=I_C03_PN14_PRODMD_STAT_ST3_SNA (SNA) (SNA value from data type)}, range raw 0..7 "03_PN14_ProdMd_Stat_ST3", transfer-property=PENDING, to CIVIC_M_P_STAR_35_ExecutionContext  # Powernet production mode state
    signal PN14_SupBat_Volt_ST3: start 22, 10 bit, little-endian, data-type-policy=OVERRIDE, i-signal-type=PRIMITIVE, base-type=uint161, invalid-value=1023, compu {phys=raw*0.025 for raw 0..1022, 1023=I_C10_V_0_25K55_0K025_SNA (SNA) (SNA value from data type); unit V}, range phys 0..25.575, raw 0..1023 "10_V_0-25,55_0,025", transfer-property=PENDING, to CIVIC_M_P_STAR_35_ExecutionContext  # Supply battery voltage
    mapping PN14_DDP_Sw2_Stat_ST3: transfer-property=PENDING
    mapping PN14_DDP_Sw_Stat_ST3: transfer-property=PENDING
    mapping PN14_ExtBat_Charge_Actv_ST3: transfer-property=PENDING
    mapping PN14_PNSec_RechargeEnable_ST3: transfer-property=PENDING
    mapping PN14_ProdMd_BatStat_ST3: transfer-property=PENDING
    mapping PN14_SupBat_Curr_ST3: transfer-property=PENDING
    mapping PN14_SupBat_Stat_ST3: transfer-property=PENDING
    mapping PN14_SupBat_Temp_ST3: transfer-property=PENDING
    mapping SignalIPDUAssignment14820: i-signal-group=PN14_Master_Stat1_ST3
  pdu PT4_PTCoor4_ST3: length=4, minimum-delay=0.01, unused-bit-pattern=255
    signal PT4_PTCoor_EngStartPN14_Stat_ST3: start 28, 3 bit, little-endian, data-type-policy=OVERRIDE, i-signal-type=PRIMITIVE, base-type=uint8, invalid-value=7, compu {0=I_C03_ENGSTARTPN14_STAT_NO_COMBUSTIONSTART_RQ (NO_COMBUSTIONSTART_RQ) (No combustion start required), 1=I_C03_ENGSTARTPN14_STAT_CUSTOMER_START_RQ (CUSTOMER_START_RQ) (Customer start required), 2=I_C03_ENGSTARTPN14_STAT_AUTO_START_NO_PN_SUP_RQ (AUTO_START_NO_PN_SUP_RQ) (Automatic start without Powernet support required), 3=I_C03_ENGSTARTPN14_STAT_AUTO_START_PN_SUP_RQ (AUTO_START_PN_SUP_RQ) (Automatic start with Powernet support required), 7=I_C03_ENGSTARTPN14_STAT_SNA (SNA) (SNA value from data type)}, range raw 0..7 "03_EngStartPN14_Stat_ST3", to CIVIC_M_P_STAR_35_ExecutionContext  # PT4 Engine Start PN14 State
    mapping CRC_PT4_PTCoor4_Pr5_ST3: transfer-property=PENDING
    mapping PT4_PTCoor4_Pr5_ST3_af4fxb1ykieox3itqdfzs0kpb: i-signal-group=PT4_PTCoor4_Pr5_ST3_af4fxb1ykieox3itqdfzs0kpb, transfer-property=TRIGGERED-ON-CHANGE
    mapping PT4_PTCoor_PT_Rdy_ST3: transfer-property=PENDING
    mapping PT4_PTCoor_SSA_EngSp_ST3: transfer-property=PENDING
    mapping Rsrv1_PT4_PTCoor_PT_Rdy_Pr5_ST3: transfer-property=PENDING
    mapping SQC_PT4_PTCoor4_Pr5_ST3: transfer-property=PENDING
  pdu TSSR_UI_Ctrl_Rq_ST3: length=4, minimum-delay=0.01, unused-bit-pattern=255  # Tilt/slide sunroof User Interaction control request
    signal TSSR_Sw_Stat_ST3: start 24, 4 bit, little-endian, data-type-policy=OVERRIDE, i-signal-type=PRIMITIVE, base-type=uint8, invalid-value=15, compu {0=I_C04_TSSR_SW_STAT_ST3_NOT_PSD (NOT_PSD) (not pressed), 1=I_C04_TSSR_SW_STAT_ST3_TSSR_AUTO_OPN (TSSR_AUTO_OPN) (Tilt/slide sunroof automatic open), 2=I_C04_TSSR_SW_STAT_ST3_LR_AUTO_OPN (LR_AUTO_OPN) (Lifting roof automatic open), 3=I_C04_TSSR_SW_STAT_ST3_LR_AUTO_CLS (LR_AUTO_CLS) (Lifting roof automatic close), 4=I_C04_TSSR_SW_STAT_ST3_LR_MAN_PSD (LR_MAN_PSD) (Lifting roof manual pressed), 5=I_C04_TSSR_SW_STAT_ST3_TSSR_MAN_OPN (TSSR_MAN_OPN) (Tilt/slide sunroof manual open), 6=I_C04_TSSR_SW_STAT_ST3_TSSR_MAN_CLS (TSSR_MAN_CLS) (Tilt/slide sunroof manual close), 7=I_C04_TSSR_SW_STAT_ST3_LR_MAN_OPN (LR_MAN_OPN) (Lifting roof manual open), 8=I_C04_TSSR_SW_STAT_ST3_LR_MAN_CLS (LR_MAN_CLS) (Lifting roof manual close), 14=I_C04_TSSR_SW_STAT_ST3_LR_STOP (LR_STOP) (Lifting roof stop), 15=I_C04_TSSR_SW_STAT_ST3_SNA (SNA) (SNA value from data type)}, range raw 0..15 "04_TSSR_Sw_Stat_ST3", to CIVIC_M_P_STAR_35_ExecutionContext  # Tilt/slide sunroof switch state (touch slider)
    signal TSSR_RB_Sw_Psd_ST3: start 28, 2 bit, little-endian, data-type-policy=OVERRIDE, i-signal-type=PRIMITIVE, base-type=uint8, invalid-value=3, compu {0=I_C02_NPSD_PSD_NDEF_NPSD (NPSD) (Not pressed), 1=I_C02_NPSD_PSD_NDEF_PSD (PSD) (Pressed), 3=I_C02_NPSD_PSD_NDEF_SNA (SNA) (SNA value from data type)} "DO NOT USE for future implementation of STAR3 and following architectures. Use 02_NotPsd_Psd instead.", range raw 0..3 "02_NPsd_Psd_NDef", to CIVIC_M_P_STAR_35_ExecutionContext  # Tilt/slide sunroof roller blind switch pressed
    mapping CRC_TSSR_Sw_Stat_Pr5_ST3: transfer-property=PENDING
    mapping Rsrv1_TSSR_Sw_Stat_Pr5_ST3: transfer-property=PENDING
    mapping SQC_TSSR_Sw_Stat_Pr5_ST3: transfer-property=PENDING
    mapping TSSR_Sw_Stat_Pr5_ST3_8ceburbz69g38mpejoxe7iisu: i-signal-group=TSSR_Sw_Stat_Pr5_ST3_8ceburbz69g38mpejoxe7iisu, transfer-property=TRIGGERED-ON-CHANGE
  pdu VSS_TP_Auth_ST3: length=8, minimum-delay=0.02, unused-bit-pattern=255  # Vehicle Security System Transport Protocol for authentication broadcast
    signal VSS_TP_Auth_0_ST3: start 0, 8 bit, little-endian, data-type-policy=OVERRIDE, i-signal-type=PRIMITIVE, base-type=uint8, data-constr=c08_UInt_SNA_na, to CIVIC_M_P_STAR_35_ExecutionContext  # Vehicle Security System Transport Protocol for authentication broadcast, Byte 0
    signal VSS_TP_Auth_1_ST3: start 8, 8 bit, little-endian, data-type-policy=OVERRIDE, i-signal-type=PRIMITIVE, base-type=uint8, data-constr=c08_UInt_SNA_na, to CIVIC_M_P_STAR_35_ExecutionContext  # Vehicle Security System Transport Protocol for authentication broadcast, Byte 1
    signal VSS_TP_Auth_2_ST3: start 16, 8 bit, little-endian, data-type-policy=OVERRIDE, i-signal-type=PRIMITIVE, base-type=uint8, data-constr=c08_UInt_SNA_na, to CIVIC_M_P_STAR_35_ExecutionContext  # Vehicle Security System Transport Protocol for authentication broadcast, Byte 2
    signal VSS_TP_Auth_3_ST3: start 24, 8 bit, little-endian, data-type-policy=OVERRIDE, i-signal-type=PRIMITIVE, base-type=uint8, data-constr=c08_UInt_SNA_na, to CIVIC_M_P_STAR_35_ExecutionContext  # Vehicle Security System Transport Protocol for authentication broadcast, Byte 3
    signal VSS_TP_Auth_4_ST3: start 32, 8 bit, little-endian, data-type-policy=OVERRIDE, i-signal-type=PRIMITIVE, base-type=uint8, data-constr=c08_UInt_SNA_na, to CIVIC_M_P_STAR_35_ExecutionContext  # Vehicle Security System Transport Protocol for authentication broadcast, Byte 4
    signal VSS_TP_Auth_5_ST3: start 40, 8 bit, little-endian, data-type-policy=OVERRIDE, i-signal-type=PRIMITIVE, base-type=uint8, data-constr=c08_UInt_SNA_na, to CIVIC_M_P_STAR_35_ExecutionContext  # Vehicle Security System Transport Protocol for authentication broadcast, Byte 5
    signal VSS_TP_Auth_6_ST3: start 48, 8 bit, little-endian, data-type-policy=OVERRIDE, i-signal-type=PRIMITIVE, base-type=uint8, data-constr=c08_UInt_SNA_na, to CIVIC_M_P_STAR_35_ExecutionContext  # Vehicle Security System Transport Protocol for authentication broadcast, Byte 6
    signal VSS_TP_Auth_7_ST3: start 56, 8 bit, little-endian, data-type-policy=OVERRIDE, i-signal-type=PRIMITIVE, base-type=uint8, data-constr=c08_UInt_SNA_na, to CIVIC_M_P_STAR_35_ExecutionContext  # Vehicle Security System Transport Protocol for authentication broadcast, Byte 7
    mapping VSS_TP_Auth_ST3_6j4id7sghlvlbroli4wjozjik: i-signal-group=VSS_TP_Auth_ST3_6j4id7sghlvlbroli4wjozjik, transfer-property=TRIGGERED
  pdu VSS_TP_RealTmOffset_ST3: length=8, minimum-delay=0.02, unused-bit-pattern=255  # Vehicle Security System Transport Protocol for real time offset broadcast
    signal VSS_TP_RealTmOffset_0_ST3: start 0, 8 bit, little-endian, data-type-policy=OVERRIDE, i-signal-type=PRIMITIVE, base-type=uint8, data-constr=c08_UInt_SNA_na, to CIVIC_M_P_STAR_35_ExecutionContext  # Vehicle Security System Transport Protocol for real time offset broadcast, Byte 0
    signal VSS_TP_RealTmOffset_1_ST3: start 8, 8 bit, little-endian, data-type-policy=OVERRIDE, i-signal-type=PRIMITIVE, base-type=uint8, data-constr=c08_UInt_SNA_na, to CIVIC_M_P_STAR_35_ExecutionContext  # Vehicle Security System Transport Protocol for real time offset broadcast, Byte 1
    signal VSS_TP_RealTmOffset_2_ST3: start 16, 8 bit, little-endian, data-type-policy=OVERRIDE, i-signal-type=PRIMITIVE, base-type=uint8, data-constr=c08_UInt_SNA_na, to CIVIC_M_P_STAR_35_ExecutionContext  # Vehicle Security System Transport Protocol for real time offset broadcast, Byte 2
    signal VSS_TP_RealTmOffset_3_ST3: start 24, 8 bit, little-endian, data-type-policy=OVERRIDE, i-signal-type=PRIMITIVE, base-type=uint8, data-constr=c08_UInt_SNA_na, to CIVIC_M_P_STAR_35_ExecutionContext  # Vehicle Security System Transport Protocol for real time offset broadcast, Byte 3
    signal VSS_TP_RealTmOffset_4_ST3: start 32, 8 bit, little-endian, data-type-policy=OVERRIDE, i-signal-type=PRIMITIVE, base-type=uint8, data-constr=c08_UInt_SNA_na, to CIVIC_M_P_STAR_35_ExecutionContext  # Vehicle Security System Transport Protocol for real time offset broadcast, Byte 4
    signal VSS_TP_RealTmOffset_5_ST3: start 40, 8 bit, little-endian, data-type-policy=OVERRIDE, i-signal-type=PRIMITIVE, base-type=uint8, data-constr=c08_UInt_SNA_na, to CIVIC_M_P_STAR_35_ExecutionContext  # Vehicle Security System Transport Protocol for real time offset broadcast, Byte 5
    signal VSS_TP_RealTmOffset_6_ST3: start 48, 8 bit, little-endian, data-type-policy=OVERRIDE, i-signal-type=PRIMITIVE, base-type=uint8, data-constr=c08_UInt_SNA_na, to CIVIC_M_P_STAR_35_ExecutionContext  # Vehicle Security System Transport Protocol for real time offset broadcast, Byte 6
    signal VSS_TP_RealTmOffset_7_ST3: start 56, 8 bit, little-endian, data-type-policy=OVERRIDE, i-signal-type=PRIMITIVE, base-type=uint8, data-constr=c08_UInt_SNA_na, to CIVIC_M_P_STAR_35_ExecutionContext  # Vehicle Security System Transport Protocol for real time offset broadcast, Byte 7
    mapping VSS_TP_RealTmOffset_ST3_1t7vc44gftc0wv35k5kgc2in9: i-signal-group=VSS_TP_RealTmOffset_ST3_1t7vc44gftc0wv35k5kgc2in9, transfer-property=TRIGGERED
  pdu VSS_TP_SecTickCount_Lvl1_ST3: length=8, minimum-delay=0.02, unused-bit-pattern=255  # Vehicle Security System Transport Protocol for secure tick count level #1
    signal VSS_TP_SecTickCount_Lvl1_0_ST3: start 0, 8 bit, little-endian, data-type-policy=OVERRIDE, i-signal-type=PRIMITIVE, base-type=uint8, data-constr=c08_UInt_SNA_na, to CIVIC_M_P_STAR_35_ExecutionContext  # Vehicle Security System Transport Protocol for secure tick count level #1, Byte 0
    signal VSS_TP_SecTickCount_Lvl1_1_ST3: start 8, 8 bit, little-endian, data-type-policy=OVERRIDE, i-signal-type=PRIMITIVE, base-type=uint8, data-constr=c08_UInt_SNA_na, to CIVIC_M_P_STAR_35_ExecutionContext  # Vehicle Security System Transport Protocol for secure tick count level #1, Byte 1
    signal VSS_TP_SecTickCount_Lvl1_2_ST3: start 16, 8 bit, little-endian, data-type-policy=OVERRIDE, i-signal-type=PRIMITIVE, base-type=uint8, data-constr=c08_UInt_SNA_na, to CIVIC_M_P_STAR_35_ExecutionContext  # Vehicle Security System Transport Protocol for secure tick count level #1, Byte 2
    signal VSS_TP_SecTickCount_Lvl1_3_ST3: start 24, 8 bit, little-endian, data-type-policy=OVERRIDE, i-signal-type=PRIMITIVE, base-type=uint8, data-constr=c08_UInt_SNA_na, to CIVIC_M_P_STAR_35_ExecutionContext  # Vehicle Security System Transport Protocol for secure tick count level #1, Byte 3
    signal VSS_TP_SecTickCount_Lvl1_4_ST3: start 32, 8 bit, little-endian, data-type-policy=OVERRIDE, i-signal-type=PRIMITIVE, base-type=uint8, data-constr=c08_UInt_SNA_na, to CIVIC_M_P_STAR_35_ExecutionContext  # Vehicle Security System Transport Protocol for secure tick count level #1, Byte 4
    signal VSS_TP_SecTickCount_Lvl1_5_ST3: start 40, 8 bit, little-endian, data-type-policy=OVERRIDE, i-signal-type=PRIMITIVE, base-type=uint8, data-constr=c08_UInt_SNA_na, to CIVIC_M_P_STAR_35_ExecutionContext  # Vehicle Security System Transport Protocol for secure tick count level #1, Byte 5
    signal VSS_TP_SecTickCount_Lvl1_6_ST3: start 48, 8 bit, little-endian, data-type-policy=OVERRIDE, i-signal-type=PRIMITIVE, base-type=uint8, data-constr=c08_UInt_SNA_na, to CIVIC_M_P_STAR_35_ExecutionContext  # Vehicle Security System Transport Protocol for secure tick count level #1, Byte 6
    signal VSS_TP_SecTickCount_Lvl1_7_ST3: start 56, 8 bit, little-endian, data-type-policy=OVERRIDE, i-signal-type=PRIMITIVE, base-type=uint8, data-constr=c08_UInt_SNA_na, to CIVIC_M_P_STAR_35_ExecutionContext  # Vehicle Security System Transport Protocol for secure tick count level #1, Byte 7
    mapping VSS_TP_SecTickCount_Lvl1_ST3_mzmfdqtqz5kvv1kfpvg0kql3: i-signal-group=VSS_TP_SecTickCount_Lvl1_ST3_mzmfdqtqz5kvv1kfpvg0kql3, transfer-property=TRIGGERED
  pdu VSS_TP_SharedSecret_ST3: length=8, minimum-delay=0.02, unused-bit-pattern=255  # Vehicle Security System Transport Protocol for shared secret broadcast
    signal VSS_TP_SharedSecret_0_ST3: start 0, 8 bit, little-endian, data-type-policy=OVERRIDE, i-signal-type=PRIMITIVE, base-type=uint8, data-constr=c08_UInt_SNA_na, to CIVIC_M_P_STAR_35_ExecutionContext  # Vehicle Security System Transport Protocol for shared secret broadcast, Byte 0
    signal VSS_TP_SharedSecret_1_ST3: start 8, 8 bit, little-endian, data-type-policy=OVERRIDE, i-signal-type=PRIMITIVE, base-type=uint8, data-constr=c08_UInt_SNA_na, to CIVIC_M_P_STAR_35_ExecutionContext  # Vehicle Security System Transport Protocol for shared secret broadcast, Byte 1
    signal VSS_TP_SharedSecret_2_ST3: start 16, 8 bit, little-endian, data-type-policy=OVERRIDE, i-signal-type=PRIMITIVE, base-type=uint8, data-constr=c08_UInt_SNA_na, to CIVIC_M_P_STAR_35_ExecutionContext  # Vehicle Security System Transport Protocol for shared secret broadcast, Byte 2
    signal VSS_TP_SharedSecret_3_ST3: start 24, 8 bit, little-endian, data-type-policy=OVERRIDE, i-signal-type=PRIMITIVE, base-type=uint8, data-constr=c08_UInt_SNA_na, to CIVIC_M_P_STAR_35_ExecutionContext  # Vehicle Security System Transport Protocol for shared secret broadcast, Byte 3
    signal VSS_TP_SharedSecret_4_ST3: start 32, 8 bit, little-endian, data-type-policy=OVERRIDE, i-signal-type=PRIMITIVE, base-type=uint8, data-constr=c08_UInt_SNA_na, to CIVIC_M_P_STAR_35_ExecutionContext  # Vehicle Security System Transport Protocol for shared secret broadcast, Byte 4
    signal VSS_TP_SharedSecret_5_ST3: start 40, 8 bit, little-endian, data-type-policy=OVERRIDE, i-signal-type=PRIMITIVE, base-type=uint8, data-constr=c08_UInt_SNA_na, to CIVIC_M_P_STAR_35_ExecutionContext  # Vehicle Security System Transport Protocol for shared secret broadcast, Byte 5
    signal VSS_TP_SharedSecret_6_ST3: start 48, 8 bit, little-endian, data-type-policy=OVERRIDE, i-signal-type=PRIMITIVE, base-type=uint8, data-constr=c08_UInt_SNA_na, to CIVIC_M_P_STAR_35_ExecutionContext  # Vehicle Security System Transport Protocol for shared secret broadcast, Byte 6
    signal VSS_TP_SharedSecret_7_ST3: start 56, 8 bit, little-endian, data-type-policy=OVERRIDE, i-signal-type=PRIMITIVE, base-type=uint8, data-constr=c08_UInt_SNA_na, to CIVIC_M_P_STAR_35_ExecutionContext  # Vehicle Security System Transport Protocol for shared secret broadcast, Byte 7
    mapping VSS_TP_SharedSecret_ST3_8pj4t8t4rm3tw3pk5hj7vonti: i-signal-group=VSS_TP_SharedSecret_ST3_8pj4t8t4rm3tw3pk5hj7vonti, transfer-property=TRIGGERED
  pdu VSS_TP_VIN_ST3: length=8, minimum-delay=0.02, unused-bit-pattern=255  # Vehicle Security System Transport Protocol for Vehicle Identification Number
    signal VSS_TP_VIN_0_ST3: start 0, 8 bit, little-endian, data-type-policy=OVERRIDE, i-signal-type=PRIMITIVE, base-type=uint8, data-constr=c08_UInt_SNA_na, to CIVIC_M_P_STAR_35_ExecutionContext  # Vehicle Security System Transport Protocol for Vehicle Identification Number, Byte 0
    signal VSS_TP_VIN_1_ST3: start 8, 8 bit, little-endian, data-type-policy=OVERRIDE, i-signal-type=PRIMITIVE, base-type=uint8, data-constr=c08_UInt_SNA_na, to CIVIC_M_P_STAR_35_ExecutionContext  # Vehicle Security System Transport Protocol for Vehicle Identification Number, Byte 1
    signal VSS_TP_VIN_2_ST3: start 16, 8 bit, little-endian, data-type-policy=OVERRIDE, i-signal-type=PRIMITIVE, base-type=uint8, data-constr=c08_UInt_SNA_na, to CIVIC_M_P_STAR_35_ExecutionContext  # Vehicle Security System Transport Protocol for Vehicle Identification Number, Byte 2
    signal VSS_TP_VIN_3_ST3: start 24, 8 bit, little-endian, data-type-policy=OVERRIDE, i-signal-type=PRIMITIVE, base-type=uint8, data-constr=c08_UInt_SNA_na, to CIVIC_M_P_STAR_35_ExecutionContext  # Vehicle Security System Transport Protocol for Vehicle Identification Number, Byte 3
    signal VSS_TP_VIN_4_ST3: start 32, 8 bit, little-endian, data-type-policy=OVERRIDE, i-signal-type=PRIMITIVE, base-type=uint8, data-constr=c08_UInt_SNA_na, to CIVIC_M_P_STAR_35_ExecutionContext  # Vehicle Security System Transport Protocol for Vehicle Identification Number, Byte 4
    signal VSS_TP_VIN_5_ST3: start 40, 8 bit, little-endian, data-type-policy=OVERRIDE, i-signal-type=PRIMITIVE, base-type=uint8, data-constr=c08_UInt_SNA_na, to CIVIC_M_P_STAR_35_ExecutionContext  # Vehicle Security System Transport Protocol for Vehicle Identification Number, Byte 5
    signal VSS_TP_VIN_6_ST3: start 48, 8 bit, little-endian, data-type-policy=OVERRIDE, i-signal-type=PRIMITIVE, base-type=uint8, data-constr=c08_UInt_SNA_na, to CIVIC_M_P_STAR_35_ExecutionContext  # Vehicle Security System Transport Protocol for Vehicle Identification Number, Byte 6
    signal VSS_TP_VIN_7_ST3: start 56, 8 bit, little-endian, data-type-policy=OVERRIDE, i-signal-type=PRIMITIVE, base-type=uint8, data-constr=c08_UInt_SNA_na, to CIVIC_M_P_STAR_35_ExecutionContext  # Vehicle Security System Transport Protocol for Vehicle Identification Number, Byte 7
    mapping VSS_TP_VIN_ST3_bz1xsv84cxzl09j028gn39p69: i-signal-group=VSS_TP_VIN_ST3_bz1xsv84cxzl09j028gn39p69, transfer-property=TRIGGERED
  pdu WprWashSw_Stat_ST3: length=4, minimum-delay=0.02, unused-bit-pattern=255  # Wiper Wisher Switch State
    signal WprSw6Posn_ST3: start 24, 3 bit, little-endian, data-type-policy=OVERRIDE, i-signal-type=PRIMITIVE, base-type=uint8, invalid-value=7, compu {0=I_C03_WPRSW6POSN_OFF (OFF) (Wiper switch stage 0 (off)), 1=I_C03_WPRSW6POSN_INTERVAL1 (INTERVAL1) (Wiper switch stage I (interval 1)), 2=I_C03_WPRSW6POSN_INTERVAL2 (INTERVAL2) (Wiper switch stage II (interval 2)), 3=I_C03_WPRSW6POSN_INTERVAL3 (INTERVAL3) (Wiper switch stage III (interval 3)), 4=I_C03_WPRSW6POSN_INTERVAL4 (INTERVAL4) (Wiper switch stage IV (interval 4)), 5=I_C03_WPRSW6POSN_STAGE1 (STAGE1) (Wiper switch stage V (stage 1)), 6=I_C03_WPRSW6POSN_STAGE2 (STAGE2) (Wiper switch stage VI (stage 2)), 7=I_C03_WPRSW6POSN_SNA (SNA) (SNA value from data type)}, range raw 0..7 "03_WprSw6Posn", to CIVIC_M_P_STAR_35_ExecutionContext  # Wiper switch (6 stages) position
    signal WprWash_R_Sw_Posn_ST3: start 27, 3 bit, little-endian, data-type-policy=OVERRIDE, i-signal-type=PRIMITIVE, base-type=uint8, invalid-value=7, compu {0=I_C03_WPRWASH_R_SW_POSN_V3_NPSD (NPSD) (Not Pressed), 1=I_C03_WPRWASH_R_SW_POSN_V3_INTERVAL (INTERVAL) (Backlite wiper/washer switch stage 1 (interval)), 2=I_C03_WPRWASH_R_SW_POSN_V3_TIPWIPE (TIPWIPE) (Backlite tip wiping pressed), 3=I_C03_WPRWASH_R_SW_POSN_V3_WASH (WASH) (Backlite wiper/washer switch washing pressed), 7=I_C03_WPRWASH_R_SW_POSN_V3_SNA (SNA) (SNA value from data type)}, range raw 0..7 "03_WprWash_R_Sw_Posn_V3", to CIVIC_M_P_STAR_35_ExecutionContext  # Backlite wiper/washer switch position
    signal WprWashSw_Psd_ST3: start 30, 2 bit, little-endian, data-type-policy=OVERRIDE, i-signal-type=PRIMITIVE, base-type=uint8, invalid-value=3, compu {0=I_C02_WPRSW_STAT_NPSD (NPSD) (Wiper/washer switch not pressed), 1=I_C02_WPRSW_STAT_TIPWIPE (TIPWIPE) (Tip wiping pressed), 2=I_C02_WPRSW_STAT_WASH (WASH) (Washing pressed), 3=I_C02_WPRSW_STAT_SNA (SNA) (SNA value from data type)}, range raw 0..3 "02_WprSw_Stat", to CIVIC_M_P_STAR_35_ExecutionContext  # Wiper/washer switch pressed
    mapping CRC_WprWashSw_Stat_Pr5_ST3: transfer-property=PENDING
    mapping SQC_WprWashSw_Stat_Pr5_ST3: transfer-property=PENDING
    mapping WprWashSw_Stat_Pr5_ST3_36s5c6vedknu08tbfk7pkbooj: i-signal-group=WprWashSw_Stat_Pr5_ST3_36s5c6vedknu08tbfk7pkbooj, transfer-property=TRIGGERED-ON-CHANGE
  pdu RB_R_UI_Ctrl_HU_Stat_ST3: length=1, transmission-mode-true-timing=event-controlled-timing=number-of-repetitions=0, unused-bit-pattern=255  # Status Bedienung Heckrollo von Headunit / Roller blind rear control headunit state
    signal RB_R_Rq_HU_ST3: start 0, 2 bit, little-endian, data-type-policy=OVERRIDE, i-signal-type=PRIMITIVE, init-value=3, base-type=uint8, invalid-value=3, compu {0=I_C02_IDLE_OPN_CLS_SNA_IDLE (IDLE) (Idle (not pressed)), 1=I_C02_IDLE_OPN_CLS_SNA_OPEN (OPEN) (Open pressed), 2=I_C02_IDLE_OPN_CLS_SNA_CLOSE (CLOSE) (Close pressed), 3=I_C02_IDLE_OPN_CLS_SNA_SNA (SNA) (SNA value from data type)} "Don't use for STAR3 and following architectures. Use 02_Cls_Opn_ST3 instead.", range raw 0..3 "02_Idle_Opn_Cls_SNA", transfer-property=TRIGGERED-ON-CHANGE, to CIVIC_M_P_STAR_35_ExecutionContext  # Anforderung Heckrollo von HU / Rear roller blind HU request
package /Communication/Signals
  12 x i signal group:
    DI_Odo_Pr5_ST3_e68xmtlkywxgxsdwekdjjhw3t: i-signal=Odo_ST3, system-signal-group=DI_Odo_Pr5_ST3_e68xmtlkywxgxsdwekdjjhw3t  # DriverInformation Odometer (degraded)
    ECU_Stat_CIVIC_M_P_ST3: i-signal=[Awake_Diag_Actv_CIVIC_M_P_ST3, Awake_HAD_Actv_CIVIC_M_P_ST3, Awake_Ignition_On_CIVIC_M_P_ST3, Awake_NwStart_CIVIC_M_P_ST3, ECU_Id_CIVIC_M_P_ST3, WakeupRsn_CIVIC_M_P_ST3], system-signal-group=ECU_Stat_CIVIC_M_P_ST3
    Ign_Stat_Pr5_ST3_csgs1dv6drms80o1i9p49677w: i-signal=ISw_Stat_ST3, system-signal-group=Ign_Stat_Pr5_ST3_csgs1dv6drms80o1i9p49677w  # Ignition state (degraded)
    PN14_Master_Stat1_ST3: i-signal=[PN14_ProdMd_Stat_ST3, PN14_SupBat_Volt_ST3, PN14_TransMd_Stat_ST3], system-signal-group=PN14_Master_Stat1_ST3
    PT4_PTCoor4_Pr5_ST3_af4fxb1ykieox3itqdfzs0kpb: i-signal=PT4_PTCoor_EngStartPN14_Stat_ST3, system-signal-group=PT4_PTCoor4_Pr5_ST3_af4fxb1ykieox3itqdfzs0kpb  # PT4_PTCoor4_Pr5_ST3 (degraded)
    TSSR_Sw_Stat_Pr5_ST3_8ceburbz69g38mpejoxe7iisu: i-signal=[TSSR_RB_Sw_Psd_ST3, TSSR_Sw_Stat_ST3], system-signal-group=TSSR_Sw_Stat_Pr5_ST3_8ceburbz69g38mpejoxe7iisu  # TSSR switch state (degraded)
    VSS_TP_Auth_ST3_6j4id7sghlvlbroli4wjozjik: i-signal=[VSS_TP_Auth_0_ST3, VSS_TP_Auth_1_ST3, VSS_TP_Auth_2_ST3, VSS_TP_Auth_3_ST3, VSS_TP_Auth_4_ST3, VSS_TP_Auth_5_ST3, VSS_TP_Auth_6_ST3, VSS_TP_Auth_7_ST3], system-signal-group=VSS_TP_Auth_ST3_6j4id7sghlvlbroli4wjozjik  # Vehicle Security System Transport Protocol for authentication broadcast (degraded)
    VSS_TP_RealTmOffset_ST3_1t7vc44gftc0wv35k5kgc2in9: i-signal=[VSS_TP_RealTmOffset_0_ST3, VSS_TP_RealTmOffset_1_ST3, VSS_TP_RealTmOffset_2_ST3, VSS_TP_RealTmOffset_3_ST3, VSS_TP_RealTmOffset_4_ST3, VSS_TP_RealTmOffset_5_ST3, VSS_TP_RealTmOffset_6_ST3, VSS_TP_RealTmOffset_7_ST3], system-signal-group=VSS_TP_RealTmOffset_ST3_1t7vc44gftc0wv35k5kgc2in9  # Vehicle Security System Transport Protocol for real time offset broadcast (degraded)
    VSS_TP_SecTickCount_Lvl1_ST3_mzmfdqtqz5kvv1kfpvg0kql3: i-signal=[VSS_TP_SecTickCount_Lvl1_0_ST3, VSS_TP_SecTickCount_Lvl1_1_ST3, VSS_TP_SecTickCount_Lvl1_2_ST3, VSS_TP_SecTickCount_Lvl1_3_ST3, VSS_TP_SecTickCount_Lvl1_4_ST3, VSS_TP_SecTickCount_Lvl1_5_ST3, VSS_TP_SecTickCount_Lvl1_6_ST3, VSS_TP_SecTickCount_Lvl1_7_ST3], system-signal-group=VSS_TP_SecTickCount_Lvl1_ST3_mzmfdqtqz5kvv1kfpvg0kql3  # Vehicle Security System Transport Protocol for secure tick count level #1 (degraded)
    VSS_TP_SharedSecret_ST3_8pj4t8t4rm3tw3pk5hj7vonti: i-signal=[VSS_TP_SharedSecret_0_ST3, VSS_TP_SharedSecret_1_ST3, VSS_TP_SharedSecret_2_ST3, VSS_TP_SharedSecret_3_ST3, VSS_TP_SharedSecret_4_ST3, VSS_TP_SharedSecret_5_ST3, VSS_TP_SharedSecret_6_ST3, VSS_TP_SharedSecret_7_ST3], system-signal-group=VSS_TP_SharedSecret_ST3_8pj4t8t4rm3tw3pk5hj7vonti  # Vehicle Security System Transport Protocol for shared secret broadcast (degraded)
    VSS_TP_VIN_ST3_bz1xsv84cxzl09j028gn39p69: i-signal=[VSS_TP_VIN_0_ST3, VSS_TP_VIN_1_ST3, VSS_TP_VIN_2_ST3, VSS_TP_VIN_3_ST3, VSS_TP_VIN_4_ST3, VSS_TP_VIN_5_ST3, VSS_TP_VIN_6_ST3, VSS_TP_VIN_7_ST3], system-signal-group=VSS_TP_VIN_ST3_bz1xsv84cxzl09j028gn39p69  # Vehicle Security System Transport Protocol for Vehicle Identification Number (degraded)
    WprWashSw_Stat_Pr5_ST3_36s5c6vedknu08tbfk7pkbooj: i-signal=[WprSw6Posn_ST3, WprWashSw_Psd_ST3, WprWash_R_Sw_Posn_ST3], system-signal-group=WprWashSw_Stat_Pr5_ST3_36s5c6vedknu08tbfk7pkbooj  # Wiper Wisher Switch State (degraded)
package /Communication/SystemSignalGroups
  10 x system signal group:
    DI_Odo_Pr5_ST3_e68xmtlkywxgxsdwekdjjhw3t: system-signal=Odo_ST3  # DriverInformation Odometer (degraded)
    Ign_Stat_Pr5_ST3_csgs1dv6drms80o1i9p49677w: system-signal=ISw_Stat_ST3  # Ignition state (degraded)
    PT4_PTCoor4_Pr5_ST3_af4fxb1ykieox3itqdfzs0kpb: system-signal=PT4_PTCoor_EngStartPN14_Stat_ST3  # PT4_PTCoor4_Pr5_ST3 (degraded)
    TSSR_Sw_Stat_Pr5_ST3_8ceburbz69g38mpejoxe7iisu: system-signal=[TSSR_RB_Sw_Psd_ST3, TSSR_Sw_Stat_ST3]  # TSSR switch state (degraded)
    VSS_TP_Auth_ST3_6j4id7sghlvlbroli4wjozjik: system-signal=[VSS_TP_Auth_0_ST3, VSS_TP_Auth_1_ST3, VSS_TP_Auth_2_ST3, VSS_TP_Auth_3_ST3, VSS_TP_Auth_4_ST3, VSS_TP_Auth_5_ST3, VSS_TP_Auth_6_ST3, VSS_TP_Auth_7_ST3]  # Vehicle Security System Transport Protocol for authentication broadcast (degraded)
    VSS_TP_RealTmOffset_ST3_1t7vc44gftc0wv35k5kgc2in9: system-signal=[VSS_TP_RealTmOffset_0_ST3, VSS_TP_RealTmOffset_1_ST3, VSS_TP_RealTmOffset_2_ST3, VSS_TP_RealTmOffset_3_ST3, VSS_TP_RealTmOffset_4_ST3, VSS_TP_RealTmOffset_5_ST3, VSS_TP_RealTmOffset_6_ST3, VSS_TP_RealTmOffset_7_ST3]  # Vehicle Security System Transport Protocol for real time offset broadcast (degraded)
    VSS_TP_SecTickCount_Lvl1_ST3_mzmfdqtqz5kvv1kfpvg0kql3: system-signal=[VSS_TP_SecTickCount_Lvl1_0_ST3, VSS_TP_SecTickCount_Lvl1_1_ST3, VSS_TP_SecTickCount_Lvl1_2_ST3, VSS_TP_SecTickCount_Lvl1_3_ST3, VSS_TP_SecTickCount_Lvl1_4_ST3, VSS_TP_SecTickCount_Lvl1_5_ST3, VSS_TP_SecTickCount_Lvl1_6_ST3, VSS_TP_SecTickCount_Lvl1_7_ST3]  # Vehicle Security System Transport Protocol for secure tick count level #1 (degraded)
    VSS_TP_SharedSecret_ST3_8pj4t8t4rm3tw3pk5hj7vonti: system-signal=[VSS_TP_SharedSecret_0_ST3, VSS_TP_SharedSecret_1_ST3, VSS_TP_SharedSecret_2_ST3, VSS_TP_SharedSecret_3_ST3, VSS_TP_SharedSecret_4_ST3, VSS_TP_SharedSecret_5_ST3, VSS_TP_SharedSecret_6_ST3, VSS_TP_SharedSecret_7_ST3]  # Vehicle Security System Transport Protocol for shared secret broadcast (degraded)
    VSS_TP_VIN_ST3_bz1xsv84cxzl09j028gn39p69: system-signal=[VSS_TP_VIN_0_ST3, VSS_TP_VIN_1_ST3, VSS_TP_VIN_2_ST3, VSS_TP_VIN_3_ST3, VSS_TP_VIN_4_ST3, VSS_TP_VIN_5_ST3, VSS_TP_VIN_6_ST3, VSS_TP_VIN_7_ST3]  # Vehicle Security System Transport Protocol for Vehicle Identification Number (degraded)
    WprWashSw_Stat_Pr5_ST3_36s5c6vedknu08tbfk7pkbooj: system-signal=[WprSw6Posn_ST3, WprWashSw_Psd_ST3, WprWash_R_Sw_Posn_ST3]  # Wiper Wisher Switch State (degraded)
package /DataConstraints
  range c08_UInt_SNA_na: raw 0..255  # 08_UInt_SNA=-
package /DataTypes/BaseTypes
  base type uint161: category=FIXED_LENGTH, base-type-size=16, base-type-encoding=NONE  # unsigned integer 16bit
package /DataTypes/ImplementationDataTypes
  28 x std cpp implementation data type:
    ARR_08_UInt_noSNA_8: category=ARRAY, array-size=8, cpp-template-argument{category=VALUE, template-type=uint8_t}, type-emitter=TYPE_EMITTER_ARA
      namespaces:
        symbol props PSI_16640_VSS_Service_ST3_0
        symbol props ARR_08_UInt_noSNA_8
    ByteVectorType: category=VECTOR, cpp-template-argument{category=VALUE, template-type=uint8_t}, type-emitter=TYPE_EMITTER_ARA
      namespaces:
        symbol props ns{0..2}
    ConversationHandle: type-emitter=TYPE_EMITTER_ARA, type-reference=uint16_t
      namespaces:
        symbol props ns{0..2}
    DC_BOOL: type-emitter=TYPE_EMITTER_ARA, type-reference=bool
      namespaces:
        symbol props DataTypes
        symbol props TypeRef
    DeamonRequestResponseType: category=STRUCTURE, type-emitter=TYPE_EMITTER_ARA
      namespaces:
        symbol props ns{0..2}
      cpp implementation data type element response_type: is-optional=false, type-reference=HandleType
      cpp implementation data type element job_identifier: is-optional=false, type-reference=JobIdentifier
      cpp implementation data type element value: is-optional=false, type-reference=ByteVectorType
    DiagRequestType: category=STRUCTURE, type-emitter=TYPE_EMITTER_ARA
      namespaces:
        symbol props ns{0..2}
      5 x cpp implementation data type element, all with is-optional=false:
        handle: type-reference=HandleType
        instance_handle: type-reference=InstanceHandle
        conversation_handle: type-reference=ConversationHandle
        job_identifier: type-reference=JobIdentifier
        value: type-reference=ByteVectorType
    HandleType: type-emitter=TYPE_EMITTER_ARA, type-reference=uint16_t
      namespaces:
        symbol props ns{0..2}
    InstanceHandle: type-emitter=TYPE_EMITTER_ARA, type-reference=uint32_t
      namespaces:
        symbol props ns{0..2}
    JobIdentifier: type-emitter=TYPE_EMITTER_ARA, type-reference=uint32_t
      namespaces:
        symbol props ns{0..2}
    MetaInfoType: category=ASSOCIATIVE_MAP, template-arguments=[{category=STRING, template-type=string}, {category=STRING, template-type=string}], type-emitter=TYPE_EMITTER_ARA
      namespaces:
        symbol props ns{0..2}
    REC_DI_Odo_Pr5_ST3_9t50popkpz30is106xpis1iyh: category=STRUCTURE, type-emitter=TYPE_EMITTER_ARA
      namespaces:
        symbol props PSI_12804_DI_OdoSpeedometer_Service_ST3_0
        symbol props REC_DI_Odo_Pr5_ST3_9t50popkpz30is106xpis1iyh
      cpp implementation data type element Odo_ST3: is-optional=false, type-reference=uint32_t
    REC_ECU_Stat_CIVIC_M_P_ST3: category=STRUCTURE, type-emitter=TYPE_EMITTER_ARA
      namespaces:
        symbol props DataTypes
        symbol props REC_ECU_Stat_CIVIC_M_P_ST3
      6 x cpp implementation data type element, all with is-optional=false:
        Awake_Diag_Actv_CIVIC_M_P_ST3: type-reference=DC_BOOL
        Awake_HAD_Actv_CIVIC_M_P_ST3: type-reference=DC_BOOL
        Awake_Ignition_On_CIVIC_M_P_ST3: type-reference=DC_BOOL
        Awake_NwStart_CIVIC_M_P_ST3: type-reference=DC_BOOL
        ECU_Id_CIVIC_M_P_ST3: type-reference=c12_0_4094_1_SNA
        WakeupRsn_CIVIC_M_P_ST3: type-reference=c10_WakeupRsn_ST3
    REC_Ign_Stat_Pr5_ST3_b0ko81o0x5jgvwtduf99gvzi0: category=STRUCTURE, type-emitter=TYPE_EMITTER_ARA
      namespaces:
        symbol props PSI_128_Immobilizer_Master_Service_ST3_0
        symbol props REC_Ign_Stat_Pr5_ST3_b0ko81o0x5jgvwtduf99gvzi0
      cpp implementation data type element ISw_Stat_ST3: is-optional=false, type-reference=uint8_t
    REC_PN14_Master_Stat1_ST3: category=STRUCTURE, type-emitter=TYPE_EMITTER_ARA
      namespaces:
        symbol props DataTypes
        symbol props REC_PN14_Master_Stat1_ST3
      cpp implementation data type element PN14_ProdMd_Stat_ST3: is-optional=false, type-reference=c03_PN14_ProdMd_Stat_ST3
      cpp implementation data type element PN14_SupBat_Volt_ST3: is-optional=false, type-reference=c10_V_0_25k55_0k025
      cpp implementation data type element PN14_TransMd_Stat_ST3: is-optional=false, type-reference=c02_TransMd_Stat
    REC_PT4_PTCoor4_Pr5_ST3_6v3sj55wsjghho72slblc9pby: category=STRUCTURE, type-emitter=TYPE_EMITTER_ARA
      namespaces:
        symbol props PSI_14596_PT4_PTCoor_Service_ST3_0
        symbol props REC_PT4_PTCoor4_Pr5_ST3_6v3sj55wsjghho72slblc9pby
      cpp implementation data type element PT4_PTCoor_EngStartPN14_Stat_ST3: is-optional=false, type-reference=uint8_t
    REC_TSSR_Sw_Stat_Pr5_ST3_7y1dtnin6c6u002o0wilpj2zj: category=STRUCTURE, type-emitter=TYPE_EMITTER_ARA
      namespaces:
        symbol props PSI_4234_TSSR_UI_Ctrl_Rq_Service_ST3_10
        symbol props REC_TSSR_Sw_Stat_Pr5_ST3_7y1dtnin6c6u002o0wilpj2zj
      cpp implementation data type element TSSR_RB_Sw_Psd_ST3: is-optional=false, type-reference=uint8_t
      cpp implementation data type element TSSR_Sw_Stat_ST3: is-optional=false, type-reference=uint8_t
    REC_WprWashSw_Stat_Pr5_ST3_en7lekos3iwo0omdqk2zxsfat: category=STRUCTURE, type-emitter=TYPE_EMITTER_ARA
      namespaces:
        symbol props PSI_5250_WiperWasher_UI_Ctrl_Wpr_Service_ST3_0
        symbol props REC_WprWashSw_Stat_Pr5_ST3_en7lekos3iwo0omdqk2zxsfat
      cpp implementation data type element WprSw6Posn_ST3: is-optional=false, type-reference=uint8_t
      cpp implementation data type element WprWash_R_Sw_Posn_ST3: is-optional=false, type-reference=uint8_t
      cpp implementation data type element WprWashSw_Psd_ST3: is-optional=false, type-reference=uint8_t
    bool: category=VALUE
    c02_TransMd_Stat: type-emitter=TYPE_EMITTER_ARA, type-reference=uint8_t  # 02_TransMd_Stat
      namespaces:
        symbol props DataTypes
        symbol props TypeRef
    c03_PN14_ProdMd_Stat_ST3: type-emitter=TYPE_EMITTER_ARA, type-reference=uint8_t  # 03_PN14_ProdMd_Stat_ST3
      namespaces:
        symbol props DataTypes
        symbol props TypeRef
    c10_V_0_25k55_0k025: type-emitter=TYPE_EMITTER_ARA, type-reference=uint16_t  # 10_V_0-25,55_0,025
      namespaces:
        symbol props DataTypes
        symbol props TypeRef
    c10_WakeupRsn_ST3: type-emitter=TYPE_EMITTER_ARA, type-reference=uint16_t  # 10_WakeupRsn_ST3
      namespaces:
        symbol props DataTypes
        symbol props TypeRef
    c12_0_4094_1_SNA: type-emitter=TYPE_EMITTER_ARA, type-reference=uint16_t  # 12_0-4094_1_SNA
      namespaces:
        symbol props DataTypes
        symbol props TypeRef
    string: category=STRING, type-emitter=TYPE_EMITTER_ARA
      namespaces:
        symbol props ara
        symbol props diag
    uint16_t: category=VALUE, type-emitter=cstdint
    uint32_t: category=VALUE, type-emitter=cstdint
    uint8_t: category=VALUE, type-emitter=cstdint
    c02_Idle_Opn_Cls_SNA: type-emitter=TYPE_EMITTER_ARA, type-reference=uint8_t  # 02_Idle_Opn_Cls_SNA
      namespaces:
        symbol props DataTypes
        symbol props TypeRef
package /DataTypes/ModelManagement
  mode declaration group MachineStates: initial-mode=Startup
    5 x mode:
      Running: value=0
      Startup: value=1
      Shutdown: value=2
      Restart: value=3
      Off: value=4
package /DataTypes/Units
  unit NoUnit: display-name=NoUnit
  unit V: display-name=V
  unit km: display-name=km
package /Machine
  machine CIVIC_M_P_STAR_35: machine-design=CIVIC_M_P_STAR_35_ExecutionContext
    function-groups:
      mode declaration group prototype CIVIC_M_P_STAR_35_ModeDeclarationGroupElement: type=MachineStates
      mode declaration group prototype MachineState: type=MachineStates
    processor CIVIC_M_P_STAR_35_Microprocessor
      processor core CIVIC_M_P_STAR_35_Core0: core-id=0
package /Machine/ProcessToMachineMappings
  process to machine mapping set SW_to_HW_Mappings
    5 x process to machine mapping, all with machine=CIVIC_M_P_STAR_35, shall-run-on=CIVIC_M_P_STAR_35_Core0:
      DiagnosticManagerDeamon_To_CIVIC_M_P_STAR_35_Mapping: process=DiagnosticManagerDeamon
      InternalRouting_CIVIC_M_P_ST35_Process_To_CIVIC_M_P_STAR_35_Mapping: process=InternalRouting_CIVIC_M_P_ST35_Process
      SelfDiagnosticAgent_Process_To_CIVIC_M_P_STAR_35_Mapping: process=SelfDiagnosticAgent_Process
      amsr_ssadiag_on_my_machine: process=amsr_ssadiagd
      amsr_ssasecd_To_CIVIC_M_P_STAR_35_Mapping: process=amsr_ssasecd
package /Machine/StartupConfigSets
  startup config set startupConfig
    startup config STARTUP_CONFIG_DEFAULT: scheduling-policy=SCHEDULING-POLICY-ROUND-ROBIN, scheduling-priority=20, startup-option{option-argument=./etc/application.json, option-kind=COMMAND-LINE-SHORT-FORM, option-name=c}
    startup config SsaDiag_startup_config: scheduling-policy=SCHEDULING-POLICY-ROUND-ROBIN, scheduling-priority=15
    startup config startup_config: scheduling-policy=SCHEDULING-POLICY-FIFO, scheduling-priority=20
package /ServiceInstances
  provided someip service instance PSI_14845_ECU_Stat_CIVIC_M_P_Service_ST3_10: service-interface=SomeIp_ECU_Stat_CIVIC_M_P_Service_ST3, someip-event-props=event=SomeIp_ECU_Stat_CIVIC_M_P_Service_ST3, sd-server-config=ServerSd_PSI_14845_ECU_Stat_CIVIC_M_P_Service_ST3_10, service-instance-id=10
    someip provided event group SomeIpEG_14845_1_ECU_STAT: event-group=EG_14845_1_ECU_STAT, multicast-threshold=7, sd-server-event-group-timing-config=ServerEgSd_SomeIpEG_14845_1_ECU_STAT
  provided user defined service instance SsaDiagApp_ProvidedBindingServiceInstance_DiagComApi: service-interface=DiagComApi_Binding
  7 x required someip service instance, all with required-minor-version=0:
    CSI_12804_DI_OdoSpeedometer_Service_ST3_0: service-interface=SomeIp_DI_OdoSpeedometer_Service_ST3, required-service-instance-id=1, sd-client-config=ClientSd_CSI_12804_DI_OdoSpeedometer_Service_ST3_0
      someip required event group SomeIpEG_12804_0_DI_Master_Odometer: event-group=EG_12804_0_DI_Master_Odometer, sd-client-event-group-timing-config=ClientEgSd_SomeIpEG_12804_0_DI_Master_Odometer
    CSI_128_Immobilizer_Master_Service_ST3_0: service-interface=SomeIp_Immobilizer_Master_Service_ST3, required-service-instance-id=1, sd-client-config=ClientSd_CSI_128_Immobilizer_Master_Service_ST3_0
      someip required event group SomeIpEG_128_0_Ign_Stat: event-group=EG_128_0_Ign_Stat, sd-client-event-group-timing-config=ClientEgSd_SomeIpEG_128_0_Ign_Stat
    CSI_14596_PT4_PTCoor_Service_ST3_0: service-interface=SomeIp_PT4_PTCoor_Service_ST3, required-service-instance-id=1, sd-client-config=ClientSd_CSI_14596_PT4_PTCoor_Service_ST3_0
      someip required event group SomeIpEG_14596_0_PT4_PTCoor4: event-group=EG_14596_0_PT4_PTCoor4, sd-client-event-group-timing-config=ClientEgSd_SomeIpEG_14596_0_PT4_PTCoor4
    CSI_14720_PN14_Master_Service_ST3_0: service-interface=SomeIp_PN14_Master_Service_ST3, required-service-instance-id=1, sd-client-config=ClientSd_CSI_14720_PN14_Master_Service_ST3_0
      someip required event group SomeIpEG_14720_0_PN14_Master: event-group=EG_14720_0_PN14_Master, sd-client-event-group-timing-config=ClientEgSd_SomeIpEG_14720_0_PN14_Master
    CSI_16640_VSS_Service_ST3_0: service-interface=SomeIp_VSS_Service_ST3, required-service-instance-id=1, sd-client-config=ClientSd_CSI_16640_VSS_Service_ST3_0
      someip required event group SomeIpEG_16640_0_VSS: event-group=EG_16640_0_VSS, sd-client-event-group-timing-config=ClientEgSd_SomeIpEG_16640_0_VSS
    CSI_4234_TSSR_UI_Ctrl_Rq_Service_ST3_10: service-interface=SomeIp_TSSR_UI_Ctrl_Rq_Service_ST3, required-service-instance-id=10, sd-client-config=ClientSd_CSI_4234_TSSR_UI_Ctrl_Rq_Service_ST3_10
      someip required event group SomeIpEG_4234_1_TSSR_UI_Ctrl: event-group=EG_4234_1_TSSR_UI_Ctrl, sd-client-event-group-timing-config=ClientEgSd_SomeIpEG_4234_1_TSSR_UI_Ctrl
    CSI_5250_WiperWasher_UI_Ctrl_Wpr_Service_ST3_0: service-interface=SomeIp_WiperWasher_UI_Ctrl_Wpr_Service_ST3, required-service-instance-id=1, sd-client-config=ClientSd_CSI_5250_WiperWasher_UI_Ctrl_Wpr_Service_ST3_0
      someip required event group SomeIpEG_5250_0_WprWashSw_Stat: event-group=EG_5250_0_WprWashSw_Stat, sd-client-event-group-timing-config=ClientEgSd_SomeIpEG_5250_0_WprWashSw_Stat
  required user defined service instance DiagComApi_Binding_DiagDeamon_Instance_1: service-interface=DiagComApi_Binding
  provided someip service instance PSI_4234_RollerBlindRear_UI_Ctrl_HU_Service_ST3: service-interface=SomeIp_RollerBlindRear_UI_Ctrl_HU_Service_ST3, someip-event-props=event=SomeIp_RB_R_Rq_HU_ST3, sd-server-config=ServerSd_PSI_4234_RollerBlindRear_UI_Ctrl_HU_Service_ST3, service-instance-id=10
    someip provided event group SomeIpEG_4234_1_RB_R_Rq_HU_ST3: event-group=EG_4234_1_RB_R_Rq_HU_ST3, multicast-threshold=7, sd-server-event-group-timing-config=ServerEgSd_SomeIpEG_4234_1_RB_R_Rq_HU_ST3
  required someip service instance CSI_3092_RollerBlindRear_UI_Ctrl_HU_Service_ST3: service-interface=SomeIp_RollerBlindRear_UI_Ctrl_HU_Service_ST3_210, required-minor-version=0, required-service-instance-id=10, sd-client-config=ClientSd_CSI_3092_RB_UI_Ctrl_Hu_Service_ST3
    someip required event group SomeIpEG_3092_1_RB_UI_Ctrl: event-group=EG_3092_1_RB_R_Rq_HU_ST3_210, sd-client-event-group-timing-config=ClientEgSd_SomeIpEG_3092_1_RB_UI_Ctrl
  provided someip service instance PSI_3194_TSSR_UI_Ctrl_Rq_Service_ST3_1: service-interface=SomeIp_TSSR_UI_Ctrl_Rq_Service_ST3_210, someip-event-props=event=SomeIp_TSSR_UI_Ctrl_Rq_ST3_210, sd-server-config=ServerSd_PSI_3194_TSSR_UI_Ctrl_Rq_Service_ST3_1, service-instance-id=1
    someip provided event group SomeIpEG_3194_1_RB_R_Rq_HU_ST3: event-group=EG_3194_1_TSSR_UI_Ctrl, multicast-threshold=7, sd-server-event-group-timing-config=ServerEgSd_SomeIpEG_3194_1_TSSR_UI_Ctrl_Rq_Service_ST3_1
package /ServiceInstances/ServiceInstanceToMachineMappings
  11 x someip service instance to machine mapping:
    CSI_12804_DI_OdoSpeedometer_Service_ST3_0_CIVIC_M_P_START_35_Mapping: communication-connector=CIVIC_M_P_START_35_MAIN10, service-instance=CSI_12804_DI_OdoSpeedometer_Service_ST3_0, udp-port=40000
    CSI_128_Immobilizer_Master_Service_ST3_0_CIVIC_M_P_START_35_Mapping: communication-connector=CIVIC_M_P_START_35_MAIN10, service-instance=CSI_128_Immobilizer_Master_Service_ST3_0, udp-port=40000
    CSI_14596_PT4_PTCoor_Service_ST3_0_CIVIC_M_P_START_35_Mapping: communication-connector=CIVIC_M_P_START_35_MAIN10, service-instance=CSI_14596_PT4_PTCoor_Service_ST3_0, udp-port=40000
    CSI_14720_PN14_Master_Service_ST3_0_CIVIC_M_P_START_35_Mapping: communication-connector=CIVIC_M_P_START_35_MAIN10, service-instance=CSI_14720_PN14_Master_Service_ST3_0
    CSI_16640_VSS_Service_ST3_0_CIVIC_M_P_START_35_Mapping: communication-connector=CIVIC_M_P_START_35_MAIN10, service-instance=CSI_16640_VSS_Service_ST3_0, udp-port=40000
    CSI_4234_TSSR_UI_Ctrl_Rq_Service_ST3_10_CIVIC_M_P_START_35_Mapping: communication-connector=CIVIC_M_P_START_35_MAIN10, service-instance=CSI_4234_TSSR_UI_Ctrl_Rq_Service_ST3_10, udp-port=40000
    CSI_5250_WiperWasher_UI_Ctrl_Wpr_Service_ST3_0_CIVIC_M_P_START_35_Mapping: communication-connector=CIVIC_M_P_START_35_MAIN10, service-instance=CSI_5250_WiperWasher_UI_Ctrl_Wpr_Service_ST3_0, udp-port=40000
    PSI_14845_ECU_Stat_CIVIC_M_P_Service_ST3_10_CIVIC_M_P_START_35_Mapping: communication-connector=CIVIC_M_P_START_35_MAIN127, service-instance=PSI_14845_ECU_Stat_CIVIC_M_P_Service_ST3_10, udp-port=40000
    PSI_4234_RollerBlindRear_UI_Ctrl_HU_Service_ST3_CIVIC_M_P_START_35_Mapping: communication-connector=CIVIC_M_P_START_35_MAIN10, service-instance=PSI_4234_RollerBlindRear_UI_Ctrl_HU_Service_ST3, udp-port=40000
    CSI_3092_RollerBlindRear_UI_Ctrl_HU_Service_ST3_CIVIC_M_P_START_35_Mapping: communication-connector=CIVIC_M_P_START_35_MAIN210, service-instance=CSI_3092_RollerBlindRear_UI_Ctrl_HU_Service_ST3, udp-port=60478
    PSI_3194_TSSR_UI_Ctrl_Rq_Service_ST3_10_CIVIC_M_P_START_35_Mapping: communication-connector=CIVIC_M_P_START_35_MAIN210, service-instance=PSI_3194_TSSR_UI_Ctrl_Rq_Service_ST3_1, udp-port=40000
package /ServiceInstances/ServiceInstanceToPortPrototypeMappings
  15 x service instance to port prototype mapping:
    CSI_12804_DI_OdoSpeedometer_Service_ST3_0_R_DI_OdoSpeedometer_Service_ST3_SelfDiagnosticAgent_Process_Mapping: port-prototype=SelfDiagnosticAgent_ExecutableRootSwc.R_DI_OdoSpeedometer_Service_ST3, process=SelfDiagnosticAgent_Process, service-instance=CSI_12804_DI_OdoSpeedometer_Service_ST3_0
    CSI_12804_DI_OdoSpeedometer_Service_ST3_0_R_DI_OdoSpeedometer_Service_ST3_amsr_ssasecd_Mapping: port-prototype=amsr_ssasecdRootSwc.R_DI_OdoSpeedometer_Service_ST3, process=amsr_ssasecd, service-instance=CSI_12804_DI_OdoSpeedometer_Service_ST3_0
    CSI_128_Immobilizer_Master_Service_ST3_0_R_Immobilizer_Master_Service_ST3_SelfDiagnosticAgent_Process_Mapping: port-prototype=SelfDiagnosticAgent_ExecutableRootSwc.R_Immobilizer_Master_Service_ST3, process=SelfDiagnosticAgent_Process, service-instance=CSI_128_Immobilizer_Master_Service_ST3_0
    CSI_128_Immobilizer_Master_Service_ST3_0_R_Immobilizer_Master_Service_ST3_amsr_ssasecd_Mapping: port-prototype=amsr_ssasecdRootSwc.R_Immobilizer_Master_Service_ST3, process=amsr_ssasecd, service-instance=CSI_128_Immobilizer_Master_Service_ST3_0
    CSI_14596_PT4_PTCoor_Service_ST3_0_R_PT4_PTCoor_Service_ST3_SelfDiagnosticAgent_Process_Mapping: port-prototype=SelfDiagnosticAgent_ExecutableRootSwc.R_PT4_PTCoor_Service_ST3, process=SelfDiagnosticAgent_Process, service-instance=CSI_14596_PT4_PTCoor_Service_ST3_0
    CSI_14720_PN14_Master_Service_ST3_0_R_PN14_Master_Service_ST3_SelfDiagnosticAgent_Process_Mapping: port-prototype=SelfDiagnosticAgent_ExecutableRootSwc.R_PN14_Master_Service_ST3, process=SelfDiagnosticAgent_Process, service-instance=CSI_14720_PN14_Master_Service_ST3_0
    CSI_16640_VSS_Service_ST3_0_R_VSS_Service_ST3_amsr_ssasecd_Mapping: port-prototype=amsr_ssasecdRootSwc.R_VSS_Service_ST3, process=amsr_ssasecd, service-instance=CSI_16640_VSS_Service_ST3_0
    CSI_4234_TSSR_UI_Ctrl_Rq_Service_ST3_10_R_TSSR_UI_Ctrl_Rq_Service_ST3_InternalRouting_CIVIC_M_P_ST35_Process_Mapping: port-prototype=InternalRouting_CIVIC_M_P_ST35_ExecutableRootSwc.R_TSSR_UI_Ctrl_Rq_Service_ST3, process=InternalRouting_CIVIC_M_P_ST35_Process, service-instance=CSI_4234_TSSR_UI_Ctrl_Rq_Service_ST3_10
    CSI_5250_WiperWasher_UI_Ctrl_Wpr_Service_ST3_0_R_WiperWasher_UI_Ctrl_Wpr_Service_ST3_InternalRouting_CIVIC_M_P_ST35_Process_Mapp: port-prototype=InternalRouting_CIVIC_M_P_ST35_ExecutableRootSwc.R_WiperWasher_UI_Ctrl_Wpr_Service_ST3, process=InternalRouting_CIVIC_M_P_ST35_Process, service-instance=CSI_5250_WiperWasher_UI_Ctrl_Wpr_Service_ST3_0
    DiagComApi_Binding_DiagDeamon_Instance_1_DiagComApi_toPort: port-prototype=DiagnosticManagerDeamon_ExecutableRootSwc.DiagComApiDeamonPort, process=DiagnosticManagerDeamon, service-instance=DiagComApi_Binding_DiagDeamon_Instance_1
    PSI_14845_ECU_Stat_CIVIC_M_P_Service_ST3_10_P_ECU_Stat_CIVIC_M_P_Service_ST3_InternalRouting_CIVIC_M_P_ST35_Process_Mapping: port-prototype=InternalRouting_CIVIC_M_P_ST35_ExecutableRootSwc.P_ECU_Stat_CIVIC_M_P_Service_ST3, process=InternalRouting_CIVIC_M_P_ST35_Process, service-instance=PSI_14845_ECU_Stat_CIVIC_M_P_Service_ST3_10
    SsaDiagApp_ProvidedBindingServiceInstance_DiagComApi_toPort: port-prototype=amsr_ssadiagRootSwc.amsr_DiagComApi, process=amsr_ssadiagd, service-instance=SsaDiagApp_ProvidedBindingServiceInstance_DiagComApi
    PSI_4234_RollerBlindRear_UI_Ctrl_HU_Service_ST3_R_RollerBlindRear_UI_Ctrl_HU_Service_ST3_InternalRouting_Process_Mapping: port-prototype=InternalRouting_CIVIC_M_P_ST35_ExecutableRootSwc.P_RollerBlindRear_UI_Ctrl_HU_Service_ST3, process=InternalRouting_CIVIC_M_P_ST35_Process, service-instance=PSI_4234_RollerBlindRear_UI_Ctrl_HU_Service_ST3
    CSI_3092_RollerBlindRear_UI_Ctrl_HU_Service_ST3_R_RollerBlindRear_UI_Ctrl_HU_Service_ST3_InternalRouting_Process_Mapping: port-prototype=InternalRouting_CIVIC_M_P_ST35_ExecutableRootSwc.R_RollerBlindRear_UI_Ctrl_HU_Service_ST3, process=InternalRouting_CIVIC_M_P_ST35_Process, service-instance=CSI_3092_RollerBlindRear_UI_Ctrl_HU_Service_ST3
    PSI_3194_TSSR_UI_Ctrl_Rq_Service_ST3_10_R_TSSR_UI_Ctrl_Rq_Service_ST3_InternalRouting_CIVIC_M_P_ST35__Process_Mapping: port-prototype=InternalRouting_CIVIC_M_P_ST35_ExecutableRootSwc.P_TSSR_UI_Ctrl_Rq_Service_ST3, process=InternalRouting_CIVIC_M_P_ST35_Process, service-instance=PSI_3194_TSSR_UI_Ctrl_Rq_Service_ST3_1
package /ServiceInstances/ServiceInstanceToSignalMappingSets
  11 x service instance to signal mapping set:
    CSI_12804_DI_OdoSpeedometer_Service_ST3_0_MappingSet
      service instance to signal mapping CSI_12804_DI_OdoSpeedometer_Service_ST3_0_DI_OdoSpeedometer_ST3: service-instance=CSI_12804_DI_OdoSpeedometer_Service_ST3_0
        event-element-mappings:
          {data-prototype-in-service-interface=element-in-impl-datatype={root-data-prototype=DI_OdoSpeedometer_ST3, target-data-prototype=Odo_ST3}, i-signal-triggering=Odo_ST3}
          {data-prototype-in-service-interface=element-in-impl-datatype={root-data-prototype=DI_OdoSpeedometer_ST3, target-data-prototype=Odo_ST3}, i-signal-triggering=Odo_ST3_9c3i7tw6yhgv029na2kl5tj5b}
    CSI_128_Immobilizer_Master_Service_ST3_0_MappingSet
      service instance to signal mapping CSI_128_Immobilizer_Master_Service_ST3_0_Ign_Stat_ST3: signal-based-event-element-to-i-signal-triggering-mapping{data-prototype-in-service-interface=element-in-impl-datatype={root-data-prototype=Ign_Stat_ST3, target-data-prototype=ISw_Stat_ST3}, i-signal-triggering=ISw_Stat_ST3_6ljb90e4p6aecmbrrmsvynniu}, service-instance=CSI_128_Immobilizer_Master_Service_ST3_0
    CSI_14596_PT4_PTCoor_Service_ST3_0_MappingSet
      service instance to signal mapping CSI_14596_PT4_PTCoor_Service_ST3_0_PT4_PTCoor4_ST3: signal-based-event-element-to-i-signal-triggering-mapping{data-prototype-in-service-interface=element-in-impl-datatype={root-data-prototype=PT4_PTCoor4_ST3, target-data-prototype=PT4_PTCoor_EngStartPN14_Stat_ST3}, i-signal-triggering=PT4_PTCoor_EngStartPN14_Stat_ST3_6q1ovargf5dwxc750b9q5y52c}, service-instance=CSI_14596_PT4_PTCoor_Service_ST3_0
    CSI_14720_PN14_Master_Service_ST3_0_MappingSet
      service instance to signal mapping CSI_14720_PN14_Master_Service_ST3_0_PN14_Master_Service_ST3: service-instance=CSI_14720_PN14_Master_Service_ST3_0
        event-element-mappings:
          {data-prototype-in-service-interface=element-in-impl-datatype={root-data-prototype=PN14_Master_Service_ST3/PN14_Master_Service_ST3, target-data-prototype=PN14_ProdMd_Stat_ST3}, i-signal-triggering=PN14_ProdMd_Stat_ST3_2ffyp8zxbxrzd1sgknbou5wa3}
          {data-prototype-in-service-interface=element-in-impl-datatype={root-data-prototype=PN14_Master_Service_ST3/PN14_Master_Service_ST3, target-data-prototype=PN14_SupBat_Volt_ST3}, i-signal-triggering=PN14_SupBat_Volt_ST3_60hlkxowac8jy3obo90saayds}
          {data-prototype-in-service-interface=element-in-impl-datatype={root-data-prototype=PN14_Master_Service_ST3/PN14_Master_Service_ST3, target-data-prototype=PN14_TransMd_Stat_ST3}, i-signal-triggering=PN14_TransMd_Stat_ST3_c8yymb9i5sn806w8fkod36dcr}
    CSI_16640_VSS_Service_ST3_0_MappingSet
      5 x service instance to signal mapping, all with service-instance=CSI_16640_VSS_Service_ST3_0:
        CSI_16640_VSS_Service_ST3_0_VSS_TP_Auth_ST3
          event-element-mappings:
            {data-prototype-in-service-interface=element-in-impl-datatype={root-data-prototype=VSS_Service_ST3/VSS_TP_Auth_ST3, target-data-prototype=ARR_08_UInt_noSNA_8}, i-signal-triggering=VSS_TP_Auth_0_ST3_dlgzk97bth28quajnrfjpaxxn}
            {data-prototype-in-service-interface=element-in-impl-datatype={root-data-prototype=VSS_Service_ST3/VSS_TP_Auth_ST3, target-data-prototype=ARR_08_UInt_noSNA_8}, i-signal-triggering=VSS_TP_Auth_1_ST3_5vfg4f0rx5mi9vvzg62fantpn}
            {data-prototype-in-service-interface=element-in-impl-datatype={root-data-prototype=VSS_Service_ST3/VSS_TP_Auth_ST3, target-data-prototype=ARR_08_UInt_noSNA_8}, i-signal-triggering=VSS_TP_Auth_2_ST3_chiyljql64wuumvw3f0ipf742}
            {data-prototype-in-service-interface=element-in-impl-datatype={root-data-prototype=VSS_Service_ST3/VSS_TP_Auth_ST3, target-data-prototype=ARR_08_UInt_noSNA_8}, i-signal-triggering=VSS_TP_Auth_3_ST3_58qq90dxhlvbkexm1r22pb7cd}
            {data-prototype-in-service-interface=element-in-impl-datatype={root-data-prototype=VSS_Service_ST3/VSS_TP_Auth_ST3, target-data-prototype=ARR_08_UInt_noSNA_8}, i-signal-triggering=VSS_TP_Auth_4_ST3_3o2so4vxozknfkb52wexj3ddq}
            {data-prototype-in-service-interface=element-in-impl-datatype={root-data-prototype=VSS_Service_ST3/VSS_TP_Auth_ST3, target-data-prototype=ARR_08_UInt_noSNA_8}, i-signal-triggering=VSS_TP_Auth_5_ST3_8mliaxr9g5vxdpsfwruab2nci}
            {data-prototype-in-service-interface=element-in-impl-datatype={root-data-prototype=VSS_Service_ST3/VSS_TP_Auth_ST3, target-data-prototype=ARR_08_UInt_noSNA_8}, i-signal-triggering=VSS_TP_Auth_6_ST3_6ms5y21iofk5qqnrgu1lawhh}
            {data-prototype-in-service-interface=element-in-impl-datatype={root-data-prototype=VSS_Service_ST3/VSS_TP_Auth_ST3, target-data-prototype=ARR_08_UInt_noSNA_8}, i-signal-triggering=VSS_TP_Auth_7_ST3_b3axn29ogj859r0b9ncuu31od}
        CSI_16640_VSS_Service_ST3_0_VSS_TP_RealTmOffset_ST3
          event-element-mappings:
            {data-prototype-in-service-interface=element-in-impl-datatype={root-data-prototype=VSS_Service_ST3/VSS_TP_RealTmOffset_ST3, target-data-prototype=ARR_08_UInt_noSNA_8}, i-signal-triggering=VSS_TP_RealTmOffset_0_ST3_8ad5uq6ozhi52gtnky4wv68u9}
            {data-prototype-in-service-interface=element-in-impl-datatype={root-data-prototype=VSS_Service_ST3/VSS_TP_RealTmOffset_ST3, target-data-prototype=ARR_08_UInt_noSNA_8}, i-signal-triggering=VSS_TP_RealTmOffset_1_ST3_aawt5s6a76fhzl2ynzxq9q9kx}
            {data-prototype-in-service-interface=element-in-impl-datatype={root-data-prototype=VSS_Service_ST3/VSS_TP_RealTmOffset_ST3, target-data-prototype=ARR_08_UInt_noSNA_8}, i-signal-triggering=VSS_TP_RealTmOffset_2_ST3_668fds62xetr4hedoffaxuokx}
            {data-prototype-in-service-interface=element-in-impl-datatype={root-data-prototype=VSS_Service_ST3/VSS_TP_RealTmOffset_ST3, target-data-prototype=ARR_08_UInt_noSNA_8}, i-signal-triggering=VSS_TP_RealTmOffset_3_ST3_6u2czyea03vjaoc388384f3l3}
            {data-prototype-in-service-interface=element-in-impl-datatype={root-data-prototype=VSS_Service_ST3/VSS_TP_RealTmOffset_ST3, target-data-prototype=ARR_08_UInt_noSNA_8}, i-signal-triggering=VSS_TP_RealTmOffset_4_ST3_2jrggf42eup1anw1o7hrhf7eb}
            {data-prototype-in-service-interface=element-in-impl-datatype={root-data-prototype=VSS_Service_ST3/VSS_TP_RealTmOffset_ST3, target-data-prototype=ARR_08_UInt_noSNA_8}, i-signal-triggering=VSS_TP_RealTmOffset_5_ST3_30t97jxr32fyni8fxcoi8p3tp}
            {data-prototype-in-service-interface=element-in-impl-datatype={root-data-prototype=VSS_Service_ST3/VSS_TP_RealTmOffset_ST3, target-data-prototype=ARR_08_UInt_noSNA_8}, i-signal-triggering=VSS_TP_RealTmOffset_6_ST3_3by1vbz8fb52he9jtpwv78vf2}
            {data-prototype-in-service-interface=element-in-impl-datatype={root-data-prototype=VSS_Service_ST3/VSS_TP_RealTmOffset_ST3, target-data-prototype=ARR_08_UInt_noSNA_8}, i-signal-triggering=VSS_TP_RealTmOffset_7_ST3_6056i836gsln6let2vcyqx7o}
        CSI_16640_VSS_Service_ST3_0_VSS_TP_SecTickCount_Lvl1_ST3
          event-element-mappings:
            {data-prototype-in-service-interface=element-in-impl-datatype={root-data-prototype=VSS_TP_SecTickCount_Lvl1_ST3, target-data-prototype=ARR_08_UInt_noSNA_8}, i-signal-triggering=VSS_TP_SecTickCount_Lvl1_0_ST3_a28o3eppc12sbxnp4gffywc14}
            {data-prototype-in-service-interface=element-in-impl-datatype={root-data-prototype=VSS_TP_SecTickCount_Lvl1_ST3, target-data-prototype=ARR_08_UInt_noSNA_8}, i-signal-triggering=VSS_TP_SecTickCount_Lvl1_1_ST3_qyo235aoyryfttj1g5fsakwv}
            {data-prototype-in-service-interface=element-in-impl-datatype={root-data-prototype=VSS_TP_SecTickCount_Lvl1_ST3, target-data-prototype=ARR_08_UInt_noSNA_8}, i-signal-triggering=VSS_TP_SecTickCount_Lvl1_2_ST3_9qqk7smw1r7gmeg3evv966ufq}
            {data-prototype-in-service-interface=element-in-impl-datatype={root-data-prototype=VSS_TP_SecTickCount_Lvl1_ST3, target-data-prototype=ARR_08_UInt_noSNA_8}, i-signal-triggering=VSS_TP_SecTickCount_Lvl1_3_ST3_dv7a1nrertgwdz8mqaw3fmsgr}
            {data-prototype-in-service-interface=element-in-impl-datatype={root-data-prototype=VSS_TP_SecTickCount_Lvl1_ST3, target-data-prototype=ARR_08_UInt_noSNA_8}, i-signal-triggering=VSS_TP_SecTickCount_Lvl1_4_ST3_6gyhpz57lpi4qwlmmx8ogs84l}
            {data-prototype-in-service-interface=element-in-impl-datatype={root-data-prototype=VSS_TP_SecTickCount_Lvl1_ST3, target-data-prototype=ARR_08_UInt_noSNA_8}, i-signal-triggering=VSS_TP_SecTickCount_Lvl1_5_ST3_av4gx2blxw7i5p1m0ys1zfv1x}
            {data-prototype-in-service-interface=element-in-impl-datatype={root-data-prototype=VSS_TP_SecTickCount_Lvl1_ST3, target-data-prototype=ARR_08_UInt_noSNA_8}, i-signal-triggering=VSS_TP_SecTickCount_Lvl1_6_ST3_dfz88e1scnlp1r419fcg2cy5}
            {data-prototype-in-service-interface=element-in-impl-datatype={root-data-prototype=VSS_TP_SecTickCount_Lvl1_ST3, target-data-prototype=ARR_08_UInt_noSNA_8}, i-signal-triggering=VSS_TP_SecTickCount_Lvl1_7_ST3_3l17488frx8f0vth6y5ort65o}
        CSI_16640_VSS_Service_ST3_0_VSS_TP_SharedSecret_ST3
          event-element-mappings:
            {data-prototype-in-service-interface=element-in-impl-datatype={root-data-prototype=VSS_Service_ST3/VSS_TP_SharedSecret_ST3, target-data-prototype=ARR_08_UInt_noSNA_8}, i-signal-triggering=VSS_TP_SharedSecret_0_ST3_3f7yem3ei577aobo29q4uohda}
            {data-prototype-in-service-interface=element-in-impl-datatype={root-data-prototype=VSS_Service_ST3/VSS_TP_SharedSecret_ST3, target-data-prototype=ARR_08_UInt_noSNA_8}, i-signal-triggering=VSS_TP_SharedSecret_1_ST3_7xxpz17x0tewnxv3rfmwp7z77}
            {data-prototype-in-service-interface=element-in-impl-datatype={root-data-prototype=VSS_Service_ST3/VSS_TP_SharedSecret_ST3, target-data-prototype=ARR_08_UInt_noSNA_8}, i-signal-triggering=VSS_TP_SharedSecret_2_ST3_4iyg0ealolwtr8g752hnzfbqs}
            {data-prototype-in-service-interface=element-in-impl-datatype={root-data-prototype=VSS_Service_ST3/VSS_TP_SharedSecret_ST3, target-data-prototype=ARR_08_UInt_noSNA_8}, i-signal-triggering=VSS_TP_SharedSecret_3_ST3_61o8vh9cc3evc0jfez9183j14}
            {data-prototype-in-service-interface=element-in-impl-datatype={root-data-prototype=VSS_Service_ST3/VSS_TP_SharedSecret_ST3, target-data-prototype=ARR_08_UInt_noSNA_8}, i-signal-triggering=VSS_TP_SharedSecret_4_ST3_c58xkq8tkdv44q977gtvdy3tk}
            {data-prototype-in-service-interface=element-in-impl-datatype={root-data-prototype=VSS_Service_ST3/VSS_TP_SharedSecret_ST3, target-data-prototype=ARR_08_UInt_noSNA_8}, i-signal-triggering=VSS_TP_SharedSecret_5_ST3_8rprna8ge0wo9up7xlblbtjpc}
            {data-prototype-in-service-interface=element-in-impl-datatype={root-data-prototype=VSS_Service_ST3/VSS_TP_SharedSecret_ST3, target-data-prototype=ARR_08_UInt_noSNA_8}, i-signal-triggering=VSS_TP_SharedSecret_6_ST3_3ad0xvnwurlibz2s9xk0i1q46}
            {data-prototype-in-service-interface=element-in-impl-datatype={root-data-prototype=VSS_Service_ST3/VSS_TP_SharedSecret_ST3, target-data-prototype=ARR_08_UInt_noSNA_8}, i-signal-triggering=VSS_TP_SharedSecret_7_ST3_2uxrfh7baml2o9tfq9lw988bv}
        CSI_16640_VSS_Service_ST3_0_VSS_TP_VIN_ST3
          event-element-mappings:
            {data-prototype-in-service-interface=element-in-impl-datatype={root-data-prototype=VSS_Service_ST3/VSS_TP_VIN_ST3, target-data-prototype=ARR_08_UInt_noSNA_8}, i-signal-triggering=VSS_TP_VIN_0_ST3_8gu6ss8fhs0uo6zm42mdfjpfn}
            {data-prototype-in-service-interface=element-in-impl-datatype={root-data-prototype=VSS_Service_ST3/VSS_TP_VIN_ST3, target-data-prototype=ARR_08_UInt_noSNA_8}, i-signal-triggering=VSS_TP_VIN_1_ST3_54gyh8mzoixnxudzz7wu007q0}
            {data-prototype-in-service-interface=element-in-impl-datatype={root-data-prototype=VSS_Service_ST3/VSS_TP_VIN_ST3, target-data-prototype=ARR_08_UInt_noSNA_8}, i-signal-triggering=VSS_TP_VIN_2_ST3_87qws3a1e20h2eghlfdo3yhxp}
            {data-prototype-in-service-interface=element-in-impl-datatype={root-data-prototype=VSS_Service_ST3/VSS_TP_VIN_ST3, target-data-prototype=ARR_08_UInt_noSNA_8}, i-signal-triggering=VSS_TP_VIN_3_ST3_3mir42azmxk6ncu46e5s3ihbh}
            {data-prototype-in-service-interface=element-in-impl-datatype={root-data-prototype=VSS_Service_ST3/VSS_TP_VIN_ST3, target-data-prototype=ARR_08_UInt_noSNA_8}, i-signal-triggering=VSS_TP_VIN_4_ST3_ai4ebf72k3pp8rqh6h0fyflyu}
            {data-prototype-in-service-interface=element-in-impl-datatype={root-data-prototype=VSS_Service_ST3/VSS_TP_VIN_ST3, target-data-prototype=ARR_08_UInt_noSNA_8}, i-signal-triggering=VSS_TP_VIN_5_ST3_9j6zbltbg239dzoz2qiiy5gjd}
            {data-prototype-in-service-interface=element-in-impl-datatype={root-data-prototype=VSS_Service_ST3/VSS_TP_VIN_ST3, target-data-prototype=ARR_08_UInt_noSNA_8}, i-signal-triggering=VSS_TP_VIN_6_ST3_aiczx9r4gv5h1cj0lpmxqni8u}
            {data-prototype-in-service-interface=element-in-impl-datatype={root-data-prototype=VSS_Service_ST3/VSS_TP_VIN_ST3, target-data-prototype=ARR_08_UInt_noSNA_8}, i-signal-triggering=VSS_TP_VIN_7_ST3_8cccjwnap652za6nvaulkeoj1}
    CSI_4234_TSSR_UI_Ctrl_Rq_Service_ST3_10_MappingSet
      service instance to signal mapping CSI_4234_TSSR_UI_Ctrl_Rq_Service_ST3_10_TSSR_UI_Ctrl_Rq_ST3: service-instance=CSI_4234_TSSR_UI_Ctrl_Rq_Service_ST3_10
        event-element-mappings:
          {data-prototype-in-service-interface=element-in-impl-datatype={root-data-prototype=TSSR_UI_Ctrl_Rq_Service_ST3/TSSR_UI_Ctrl_Rq_ST3, target-data-prototype=TSSR_RB_Sw_Psd_ST3}, i-signal-triggering=TSSR_RB_Sw_Psd_ST3_41hyhy1ren0bl9q9iw2f4pvok}
          {data-prototype-in-service-interface=element-in-impl-datatype={root-data-prototype=TSSR_UI_Ctrl_Rq_Service_ST3/TSSR_UI_Ctrl_Rq_ST3, target-data-prototype=TSSR_Sw_Stat_ST3}, i-signal-triggering=TSSR_Sw_Stat_ST3_ck4zpjusfx3irpxrk60v0muxv}
    CSI_5250_WiperWasher_UI_Ctrl_Wpr_Service_ST3_0_MappingSet
      service instance to signal mapping CSI_5250_WiperWasher_UI_Ctrl_Wpr_Service_ST3_0_WprWashSw_Stat_ST3: service-instance=CSI_5250_WiperWasher_UI_Ctrl_Wpr_Service_ST3_0
        event-element-mappings:
          {data-prototype-in-service-interface=element-in-impl-datatype={root-data-prototype=WprWashSw_Stat_ST3, target-data-prototype=WprSw6Posn_ST3}, i-signal-triggering=WprSw6Posn_ST3_82k2rrtfm21zwix1c96t0btmu}
          {data-prototype-in-service-interface=element-in-impl-datatype={root-data-prototype=WprWashSw_Stat_ST3, target-data-prototype=WprWashSw_Psd_ST3}, i-signal-triggering=WprWashSw_Psd_ST3_h9b3pxu1zvw4kx65gloebyjo}
          {data-prototype-in-service-interface=element-in-impl-datatype={root-data-prototype=WprWashSw_Stat_ST3, target-data-prototype=WprWash_R_Sw_Posn_ST3}, i-signal-triggering=WprWash_R_Sw_Posn_ST3_5cvkuma71080o54bxlun6irx}
    PSI_14845_ECU_Stat_CIVIC_M_P_Service_ST3_10_MappingSet
      service instance to signal mapping PSI_14845_ECU_Stat_CIVIC_M_P_Service_ST3_10_ECU_Stat_CIVIC_M_P_Service_ST3: service-instance=PSI_14845_ECU_Stat_CIVIC_M_P_Service_ST3_10
        event-element-mappings:
          {data-prototype-in-service-interface=element-in-impl-datatype={root-data-prototype=ECU_Stat_CIVIC_M_P_Service_ST3/ECU_Stat_CIVIC_M_P_Service_ST3, target-data-prototype=Awake_Diag_Actv_CIVIC_M_P_ST3}, i-signal-triggering=Awake_Diag_Actv_CIVIC_M_P_ST3_9ap8rutwcps5xywturko6jkap}
          {data-prototype-in-service-interface=element-in-impl-datatype={root-data-prototype=ECU_Stat_CIVIC_M_P_Service_ST3/ECU_Stat_CIVIC_M_P_Service_ST3, target-data-prototype=Awake_HAD_Actv_CIVIC_M_P_ST3}, i-signal-triggering=Awake_HAD_Actv_CIVIC_M_P_ST3_3wzu6uaq0325y3ev7rukipb1x}
          {data-prototype-in-service-interface=element-in-impl-datatype={root-data-prototype=ECU_Stat_CIVIC_M_P_Service_ST3/ECU_Stat_CIVIC_M_P_Service_ST3, target-data-prototype=Awake_Ignition_On_CIVIC_M_P_ST3}, i-signal-triggering=Awake_Ignition_On_CIVIC_M_P_ST3_bvl9kuk242ofwm2r390hrqkfa}
          {data-prototype-in-service-interface=element-in-impl-datatype={root-data-prototype=ECU_Stat_CIVIC_M_P_Service_ST3/ECU_Stat_CIVIC_M_P_Service_ST3, target-data-prototype=Awake_NwStart_CIVIC_M_P_ST3}, i-signal-triggering=Awake_NwStart_CIVIC_M_P_ST3_epgum0fp2w7c2ni7n9x8ddh1m}
          {data-prototype-in-service-interface=element-in-impl-datatype={root-data-prototype=ECU_Stat_CIVIC_M_P_Service_ST3/ECU_Stat_CIVIC_M_P_Service_ST3, target-data-prototype=ECU_Id_CIVIC_M_P_ST3}, i-signal-triggering=ECU_Id_CIVIC_M_P_ST3_b21od5h40erzemfwrxehmxqi6}
          {data-prototype-in-service-interface=element-in-impl-datatype={root-data-prototype=ECU_Stat_CIVIC_M_P_Service_ST3/ECU_Stat_CIVIC_M_P_Service_ST3, target-data-prototype=WakeupRsn_CIVIC_M_P_ST3}, i-signal-triggering=WakeupRsn_CIVIC_M_P_ST3_do2l7odl804hqsjdtwvl11y72}
    PSI_4234_RollerBlindRear_UI_Ctrl_HU_Service_ST3_MappingSet
      service instance to signal mapping PSI_4234_RollerBlindRear_UI_Ctrl_HU_Service_ST3_RB_R_Rq_HU_ST3: signal-based-event-element-to-i-signal-triggering-mapping{data-prototype-in-service-interface=element-in-impl-datatype={root-data-prototype=RollerBlindRear_UI_Ctrl_HU_Service_ST3/RB_R_Rq_HU_ST3, target-data-prototype=c02_Idle_Opn_Cls_SNA}, i-signal-triggering=RB_R_Rq_HU_ST3_ca6uvha22cv571lituvae6430}, service-instance=PSI_4234_RollerBlindRear_UI_Ctrl_HU_Service_ST3
    CSI_3092_RollerBlindRear_UI_Ctrl_HU_Service_ST3_MappingSet
      service instance to signal mapping CSI_3092_RollerBlindRear_UI_Ctrl_HU_Service_ST3_RB_R_Rq_HU_ST3: signal-based-event-element-to-i-signal-triggering-mapping{data-prototype-in-service-interface=element-in-impl-datatype={root-data-prototype=RollerBlindRear_UI_Ctrl_HU_Service_ST3_210/RB_R_Rq_HU_ST3, target-data-prototype=c02_Idle_Opn_Cls_SNA}, i-signal-triggering=ST_Sig_R_RollerBlindUICtrlHUST3_setRB_R_Rq_HU_ST3_setRB_R_Rq_HU_ST3_REQUEST_NO_RETURN}, service-instance=CSI_3092_RollerBlindRear_UI_Ctrl_HU_Service_ST3
    PSI_3194_TSSR_UI_Ctrl_Rq_Service_ST3_10_MappingSet
      service instance to signal mapping PSI_3194_TSSR_UI_Ctrl_Rq_Service_ST3_10_TSSR_UI_Ctrl_Rq_ST3: service-instance=PSI_3194_TSSR_UI_Ctrl_Rq_Service_ST3_1
        event-element-mappings:
          {data-prototype-in-service-interface=element-in-impl-datatype={root-data-prototype=TSSR_UI_Ctrl_Rq_Service_ST3_210/TSSR_UI_Ctrl_Rq_ST3, target-data-prototype=TSSR_RB_Sw_Psd_ST3}, i-signal-triggering=TSSR_RB_Sw_Psd_ST3_210_41hyhy1ren0bl9q9iw2f4pvok}
          {data-prototype-in-service-interface=element-in-impl-datatype={root-data-prototype=TSSR_UI_Ctrl_Rq_Service_ST3_210/TSSR_UI_Ctrl_Rq_ST3, target-data-prototype=TSSR_Sw_Stat_ST3}, i-signal-triggering=TSSR_Sw_Stat_ST3_210_ck4zpjusfx3irpxrk60v0muxv}
package /ServiceInstances/SomeipSdTimingConfigs
  7 x someip sd client event group timing config, all with request-response-delay={max-value=0, min-value=0}, time-to-live=16777215:
    ClientEgSd_SomeIpEG_12804_0_DI_Master_Odometer
    ClientEgSd_SomeIpEG_128_0_Ign_Stat
    ClientEgSd_SomeIpEG_14596_0_PT4_PTCoor4
    ClientEgSd_SomeIpEG_14720_0_PN14_Master
    ClientEgSd_SomeIpEG_16640_0_VSS
    ClientEgSd_SomeIpEG_4234_1_TSSR_UI_Ctrl
    ClientEgSd_SomeIpEG_5250_0_WprWashSw_Stat
  7 x someip sd client service instance config, all with service-find-time-to-live=16777215:
    ClientSd_CSI_12804_DI_OdoSpeedometer_Service_ST3_0: initial-find-behavior={initial-delay-max-value=0.02, initial-delay-min-value=0.02, initial-repetitions-base-delay=0.055, initial-repetitions-max=9}
    ClientSd_CSI_128_Immobilizer_Master_Service_ST3_0: initial-find-behavior={initial-delay-max-value=0, initial-delay-min-value=0, initial-repetitions-base-delay=0.055, initial-repetitions-max=9}
    ClientSd_CSI_14596_PT4_PTCoor_Service_ST3_0: initial-find-behavior={initial-delay-max-value=0.02, initial-delay-min-value=0.02, initial-repetitions-base-delay=0.055, initial-repetitions-max=9}
    ClientSd_CSI_14720_PN14_Master_Service_ST3_0: initial-find-behavior={initial-delay-max-value=0, initial-delay-min-value=0, initial-repetitions-base-delay=0.055, initial-repetitions-max=9}
    ClientSd_CSI_16640_VSS_Service_ST3_0: initial-find-behavior={initial-delay-max-value=0, initial-delay-min-value=0, initial-repetitions-base-delay=0.055, initial-repetitions-max=9}
    ClientSd_CSI_4234_TSSR_UI_Ctrl_Rq_Service_ST3_10: initial-find-behavior={initial-delay-max-value=0.02, initial-delay-min-value=0.02, initial-repetitions-base-delay=0.055, initial-repetitions-max=9}
    ClientSd_CSI_5250_WiperWasher_UI_Ctrl_Wpr_Service_ST3_0: initial-find-behavior={initial-delay-max-value=0, initial-delay-min-value=0, initial-repetitions-base-delay=0.055, initial-repetitions-max=9}
  someip sd server event group timing config ServerEgSd_SomeIpEG_14845_1_ECU_STAT: request-response-delay={max-value=0, min-value=0}
  someip sd server service instance config ServerSd_PSI_14845_ECU_Stat_CIVIC_M_P_Service_ST3_10: initial-offer-behavior={initial-delay-max-value=0, initial-delay-min-value=0, initial-repetitions-base-delay=0.22, initial-repetitions-max=2}, offer-cyclic-delay=10, request-response-delay={max-value=0, min-value=0}, service-offer-time-to-live=16777215
  someip sd server event group timing config ServerEgSd_SomeIpEG_4234_1_RB_R_Rq_HU_ST3: request-response-delay={max-value=0, min-value=0}
  someip sd server service instance config ServerSd_PSI_4234_RollerBlindRear_UI_Ctrl_HU_Service_ST3: initial-offer-behavior={initial-delay-max-value=0, initial-delay-min-value=0, initial-repetitions-base-delay=0.22, initial-repetitions-max=2}, offer-cyclic-delay=10, request-response-delay={max-value=0, min-value=0}, service-offer-time-to-live=16777215
  someip sd client event group timing config ClientEgSd_SomeIpEG_3092_1_RB_UI_Ctrl: request-response-delay={max-value=0, min-value=0}, time-to-live=16777215
  someip sd client service instance config ClientSd_CSI_3092_RB_UI_Ctrl_Hu_Service_ST3: initial-find-behavior={initial-delay-max-value=0, initial-delay-min-value=0, initial-repetitions-base-delay=0.22, initial-repetitions-max=9}, service-find-time-to-live=16777215
  someip sd server event group timing config ServerEgSd_SomeIpEG_3194_1_TSSR_UI_Ctrl_Rq_Service_ST3_1: request-response-delay={max-value=0, min-value=0}
  someip sd server service instance config ServerSd_PSI_3194_TSSR_UI_Ctrl_Rq_Service_ST3_1: initial-offer-behavior={initial-delay-max-value=0, initial-delay-min-value=0, initial-repetitions-base-delay=0.22, initial-repetitions-max=2}, offer-cyclic-delay=10, request-response-delay={max-value=0, min-value=0}, service-offer-time-to-live=16777215
package /ServiceInterfaces
  12 x service interface:
    DI_OdoSpeedometer_Service_ST3
      namespaces:
        symbol props Services
        symbol props NS_DI_OdoSpeedometer_Service_ST3
      events:
        data DI_OdoSpeedometer_ST3: type=REC_DI_Odo_Pr5_ST3_9t50popkpz30is106xpis1iyh
    DiagComApi
      namespaces:
        4 x symbol props:
          amsr
          diag
          service_interfaces
          diag_com_api
      events:
        data DaemonRequestResponse: type=DeamonRequestResponseType
        data DiagRequest: type=DiagRequestType
      methods:
        4 x operation, all with fire-and-forget=true:
          Cancel
            arg job_identifier: type=JobIdentifier, direction=IN
          NotifyResponse
            arg response_type: type=HandleType, direction=IN
            arg job_identifier: type=JobIdentifier, direction=IN
            arg byte_vector: type=ByteVectorType, direction=IN
          NotifyValue
            4 x arg, all with direction=IN:
              handle: type=HandleType
              instance_handle: type=InstanceHandle
              conversation_handle: type=ConversationHandle
              byte_vector: type=ByteVectorType
          RequestData
            6 x arg, all with direction=IN:
              handle: type=HandleType
              instance_handle: type=InstanceHandle
              job_identifier: type=JobIdentifier
              meta_info: type=MetaInfoType
              request_data: type=ByteVectorType
              conversation_handle: type=ConversationHandle
    ECU_Stat_CIVIC_M_P_Service_ST3
      namespaces:
        symbol props Services
        symbol props NS_ECU_Stat_CIVIC_M_P_Service_ST3
      events:
        data ECU_Stat_CIVIC_M_P_Service_ST3: type=REC_ECU_Stat_CIVIC_M_P_ST3
    Immobilizer_Master_Service_ST3
      namespaces:
        symbol props Services
        symbol props NS_Immobilizer_Master_Service_ST3
      events:
        data Ign_Stat_ST3: type=REC_Ign_Stat_Pr5_ST3_b0ko81o0x5jgvwtduf99gvzi0
    PN14_Master_Service_ST3
      namespaces:
        symbol props Services
        symbol props NS_PN14_Master_Service_ST3
      events:
        data PN14_Master_Service_ST3: type=REC_PN14_Master_Stat1_ST3
    PT4_PTCoor_Service_ST3
      namespaces:
        symbol props Services
        symbol props NS_PT4_PTCoor_Service_ST3
      events:
        data PT4_PTCoor4_ST3: type=REC_PT4_PTCoor4_Pr5_ST3_6v3sj55wsjghho72slblc9pby
    TSSR_UI_Ctrl_Rq_Service_ST3
      namespaces:
        symbol props Services
        symbol props NS_TSSR_UI_Ctrl_Rq_Service_ST3
      events:
        data TSSR_UI_Ctrl_Rq_ST3: type=REC_TSSR_Sw_Stat_Pr5_ST3_7y1dtnin6c6u002o0wilpj2zj
    VSS_Service_ST3
      namespaces:
        symbol props Services
        symbol props NS_VSS_Service_ST3
      events:
        5 x data, all with type=ARR_08_UInt_noSNA_8:
          VSS_TP_Auth_ST3
          VSS_TP_RealTmOffset_ST3
          VSS_TP_SecTickCount_Lvl1_ST3
          VSS_TP_SharedSecret_ST3
          VSS_TP_VIN_ST3
    WiperWasher_UI_Ctrl_Wpr_Service_ST3
      namespaces:
        symbol props Services
        symbol props NS_WiperWasher_UI_Ctrl_Wpr_Service_ST3
      events:
        data WprWashSw_Stat_ST3: type=REC_WprWashSw_Stat_Pr5_ST3_en7lekos3iwo0omdqk2zxsfat
    RollerBlindRear_UI_Ctrl_HU_Service_ST3
      namespaces:
        symbol props Services
        symbol props NS_RollerBlindRear_UI_Ctrl_HU_Service_ST3
      events:
        data RB_R_Rq_HU_ST3: type=c02_Idle_Opn_Cls_SNA
    RollerBlindRear_UI_Ctrl_HU_Service_ST3_210
      namespaces:
        symbol props Services
        symbol props NS_RollerBlindRear_UI_Ctrl_HU_Service_ST3_210
      events:
        data RB_R_Rq_HU_ST3: type=c02_Idle_Opn_Cls_SNA
    TSSR_UI_Ctrl_Rq_Service_ST3_210
      namespaces:
        symbol props Services
        symbol props NS_TSSR_UI_Ctrl_Rq_Service_ST3_210
      events:
        data TSSR_UI_Ctrl_Rq_ST3: type=REC_TSSR_Sw_Stat_Pr5_ST3_7y1dtnin6c6u002o0wilpj2zj
package /ServiceInterfaces/InterfaceMappingSets
  interface mapping set InterfaceMappingSet
    9 x interface mapping:
      DI_OdoSpeedometer_Service_ST3_InterfaceMapping
        event mapping DI_OdoSpeedometer_ST3_DI_Odo_Pr5_ST3: data-element=DI_Odo_Pr5_ST3, event=DI_OdoSpeedometer_ST3
      ECU_Stat_CIVIC_M_P_Service_ST3_InterfaceMapping
        event mapping ECU_Stat_CIVIC_M_P_Service_ST3_ECU_Stat_CIVIC_M_P_Service_ST3: data-element=ECU_Stat_CIVIC_M_P_Service_ST3/ECU_Stat_CIVIC_M_P_Service_ST3, event=ECU_Stat_CIVIC_M_P_Service_ST3/ECU_Stat_CIVIC_M_P_Service_ST3
      Immobilizer_Master_Service_ST3_InterfaceMapping
        event mapping Ign_Stat_ST3_Ign_Stat_Pr5_ST3: data-element=Ign_Stat_Pr5_ST3, event=Ign_Stat_ST3
      PN14_Master_Service_ST3_InterfaceMapping
        event mapping PN14_Master_Service_ST3_PN14_Master_Service_ST3: data-element=PN14_Master_Service_ST3/PN14_Master_Service_ST3, event=PN14_Master_Service_ST3/PN14_Master_Service_ST3
      PT4_PTCoor_Service_ST3_InterfaceMapping
        event mapping PT4_PTCoor4_ST3_PT4_PTCoor4_Pr5_ST3: data-element=PT4_PTCoor4_Pr5_ST3, event=PT4_PTCoor4_ST3
      TSSR_UI_Ctrl_Rq_Service_ST3_InterfaceMapping
        event mapping TSSR_UI_Ctrl_Rq_ST3_TSSR_Sw_Stat_Pr5_ST3: data-element=TSSR_Sw_Stat_Pr5_ST3, event=TSSR_UI_Ctrl_Rq_Service_ST3/TSSR_UI_Ctrl_Rq_ST3
      VSS_Service_ST3_InterfaceMapping
        5 x event mapping:
          VSS_TP_Auth_ST3_VSS_TP_Auth_ST3: data-element=IG_VSS_TP_Auth_ST3/VSS_TP_Auth_ST3, event=VSS_Service_ST3/VSS_TP_Auth_ST3
          VSS_TP_RealTmOffset_ST3_VSS_TP_RealTmOffset_ST3: data-element=IG_VSS_TP_RealTmOffset_ST3/VSS_TP_RealTmOffset_ST3, event=VSS_Service_ST3/VSS_TP_RealTmOffset_ST3
          VSS_TP_SecTickCount_Lvl1_ST3_VSS_TP_SecTickCount_ST3: data-element=VSS_TP_SecTickCount_ST3, event=VSS_TP_SecTickCount_Lvl1_ST3
          VSS_TP_SharedSecret_ST3_VSS_TP_SharedSecret_ST3: data-element=IG_VSS_TP_SharedSecret_ST3/VSS_TP_SharedSecret_ST3, event=VSS_Service_ST3/VSS_TP_SharedSecret_ST3
          VSS_TP_VIN_ST3_VSS_TP_VIN_ST3: data-element=IG_VSS_TP_VIN_ST3/VSS_TP_VIN_ST3, event=VSS_Service_ST3/VSS_TP_VIN_ST3
      WiperWasher_UI_Ctrl_Wpr_Service_ST3_InterfaceMapping
        event mapping WprWashSw_Stat_ST3_WprWashSw_Stat_Pr5_ST3: data-element=WprWashSw_Stat_Pr5_ST3, event=WprWashSw_Stat_ST3
      RollerBlindRear_UI_Ctrl_HU_Service_ST3_InterfaceMapping
        event mapping RB_R_Rq_HU_ST3_RollerBlinderEventName: data-element=RollerBlinderEventName, event=RollerBlindRear_UI_Ctrl_HU_Service_ST3/RB_R_Rq_HU_ST3
package /ServiceInterfaces/ServiceInterfaceDeployments
  8 x signal based service interface deployment:
    CSI_12804_DI_OdoSpeedometer_Service_ST3_0_SignalBasedDeployment: service-interface=DI_OdoSpeedometer_Service_ST3
    CSI_128_Immobilizer_Master_Service_ST3_0_SignalBasedDeployment: service-interface=Immobilizer_Master_Service_ST3
    CSI_14596_PT4_PTCoor_Service_ST3_0_SignalBasedDeployment: service-interface=PT4_PTCoor_Service_ST3
    CSI_14720_PN14_Master_Service_ST3_0_SignalBasedDeployment: service-interface=PN14_Master_Service_ST3
    CSI_16640_VSS_Service_ST3_0_SignalBasedDeployment: service-interface=VSS_Service_ST3
    CSI_4234_TSSR_UI_Ctrl_Rq_Service_ST3_10_SignalBasedDeployment: service-interface=TSSR_UI_Ctrl_Rq_Service_ST3
    CSI_5250_WiperWasher_UI_Ctrl_Wpr_Service_ST3_0_SignalBasedDeployment: service-interface=WiperWasher_UI_Ctrl_Wpr_Service_ST3
    PSI_14845_ECU_Stat_CIVIC_M_P_Service_ST3_10_SignalBasedDeployment: service-interface=ECU_Stat_CIVIC_M_P_Service_ST3
  8 x someip service interface deployment, all with service-interface-version={major-version=1, minor-version=0}:
    SomeIp_DI_OdoSpeedometer_Service_ST3: service-interface=DI_OdoSpeedometer_Service_ST3, service-interface-id=12804
      someip event deployment SomeIp_DI_OdoSpeedometer_ST3: event=DI_OdoSpeedometer_ST3, event-id=0, transport-protocol=UDP
      someip event group EG_12804_0_DI_Master_Odometer: event-group-id=0, event=SomeIp_DI_OdoSpeedometer_ST3
    SomeIp_ECU_Stat_CIVIC_M_P_Service_ST3: service-interface=ECU_Stat_CIVIC_M_P_Service_ST3, service-interface-id=14845
      someip event deployment SomeIp_ECU_Stat_CIVIC_M_P_Service_ST3: event=ECU_Stat_CIVIC_M_P_Service_ST3/ECU_Stat_CIVIC_M_P_Service_ST3, event-id=1, transport-protocol=UDP
      someip event group EG_14845_1_ECU_STAT: event-group-id=1, event=SomeIp_ECU_Stat_CIVIC_M_P_Service_ST3
    SomeIp_Immobilizer_Master_Service_ST3: service-interface=Immobilizer_Master_Service_ST3, service-interface-id=128
      someip event deployment SomeIp_Ign_Stat_ST3: event=Ign_Stat_ST3, event-id=0, transport-protocol=UDP
      someip event group EG_128_0_Ign_Stat: event-group-id=0, event=SomeIp_Ign_Stat_ST3
    SomeIp_PN14_Master_Service_ST3: service-interface=PN14_Master_Service_ST3, service-interface-id=14720
      someip event deployment SomeIp_PN14_Master_Service_ST3: event=PN14_Master_Service_ST3/PN14_Master_Service_ST3, event-id=0, transport-protocol=UDP
      someip event group EG_14720_0_PN14_Master: event-group-id=0, event=SomeIp_PN14_Master_Service_ST3
    SomeIp_PT4_PTCoor_Service_ST3: service-interface=PT4_PTCoor_Service_ST3, service-interface-id=14596
      someip event deployment SomeIp_PT4_PTCoor4_ST3: event=PT4_PTCoor4_ST3, event-id=6, transport-protocol=UDP
      someip event group EG_14596_0_PT4_PTCoor4: event-group-id=0, event=SomeIp_PT4_PTCoor4_ST3
    SomeIp_TSSR_UI_Ctrl_Rq_Service_ST3: service-interface=TSSR_UI_Ctrl_Rq_Service_ST3, service-interface-id=4234
      someip event deployment SomeIp_TSSR_UI_Ctrl_Rq_ST3: event=TSSR_UI_Ctrl_Rq_Service_ST3/TSSR_UI_Ctrl_Rq_ST3, event-id=0, transport-protocol=UDP
      someip event group EG_4234_1_TSSR_UI_Ctrl: event-group-id=1, event=SomeIp_TSSR_UI_Ctrl_Rq_ST3
    SomeIp_VSS_Service_ST3: service-interface=VSS_Service_ST3, service-interface-id=16640
      5 x someip event deployment, all with transport-protocol=UDP:
        SomeIp_VSS_TP_Auth_ST3: event=VSS_Service_ST3/VSS_TP_Auth_ST3, event-id=1
        SomeIp_VSS_TP_RealTmOffset_ST3: event=VSS_Service_ST3/VSS_TP_RealTmOffset_ST3, event-id=2
        SomeIp_VSS_TP_SecTickCount_Lvl1_ST3: event=VSS_TP_SecTickCount_Lvl1_ST3, event-id=4
        SomeIp_VSS_TP_SharedSecret_ST3: event=VSS_Service_ST3/VSS_TP_SharedSecret_ST3, event-id=3
        SomeIp_VSS_TP_VIN_ST3: event=VSS_Service_ST3/VSS_TP_VIN_ST3, event-id=0
      someip event group EG_16640_0_VSS: event-group-id=0, event=[SomeIp_VSS_TP_Auth_ST3, SomeIp_VSS_TP_RealTmOffset_ST3, SomeIp_VSS_TP_SecTickCount_Lvl1_ST3, SomeIp_VSS_TP_SharedSecret_ST3, SomeIp_VSS_TP_VIN_ST3]
    SomeIp_WiperWasher_UI_Ctrl_Wpr_Service_ST3: service-interface=WiperWasher_UI_Ctrl_Wpr_Service_ST3, service-interface-id=5250
      someip event deployment SomeIp_WprWashSw_Stat_ST3: event=WprWashSw_Stat_ST3, event-id=0, transport-protocol=UDP
      someip event group EG_5250_0_WprWashSw_Stat: event-group-id=0, event=SomeIp_WprWashSw_Stat_ST3
  user defined service interface deployment DiagComApi_Binding: service-interface=DiagComApi
    user defined event deployment CIVIC_M_P_STAR_35_DaemonRequestResponse_Event: event=DaemonRequestResponse
    user defined event deployment CIVIC_M_P_STAR_35_DiagRequest_Event: event=DiagRequest
    4 x user defined method deployment:
      CIVIC_M_P_STAR_35_Cancel_Method: method=Cancel
      CIVIC_M_P_STAR_35_NotifyResponse_Method: method=NotifyResponse
      CIVIC_M_P_STAR_35_NotifyValue_Method: method=NotifyValue
      CIVIC_M_P_STAR_35_RequestData_Method: method=RequestData
  someip service interface deployment SomeIp_RollerBlindRear_UI_Ctrl_HU_Service_ST3: service-interface=RollerBlindRear_UI_Ctrl_HU_Service_ST3, service-interface-id=4486, service-interface-version={major-version=1, minor-version=0}
    someip event deployment SomeIp_RB_R_Rq_HU_ST3: event=RollerBlindRear_UI_Ctrl_HU_Service_ST3/RB_R_Rq_HU_ST3, event-id=0, transport-protocol=UDP
    someip event group EG_4234_1_RB_R_Rq_HU_ST3: event-group-id=1, event=SomeIp_RB_R_Rq_HU_ST3
  signal based service interface deployment CSI_4234_RollerBlindRear_UI_Ctrl_HU_Service_ST3_SignalBasedDeployment: service-interface=RollerBlindRear_UI_Ctrl_HU_Service_ST3
  someip service interface deployment SomeIp_RollerBlindRear_UI_Ctrl_HU_Service_ST3_210: service-interface=RollerBlindRear_UI_Ctrl_HU_Service_ST3_210, service-interface-id=3092, service-interface-version={major-version=1, minor-version=0}
    someip event deployment SomeIp_RB_R_Rq_HU_ST3_210: event=RollerBlindRear_UI_Ctrl_HU_Service_ST3_210/RB_R_Rq_HU_ST3, event-id=0, transport-protocol=UDP
    someip event group EG_3092_1_RB_R_Rq_HU_ST3_210: event-group-id=1, event=SomeIp_RB_R_Rq_HU_ST3_210
  someip service interface deployment SomeIp_TSSR_UI_Ctrl_Rq_Service_ST3_210: service-interface=TSSR_UI_Ctrl_Rq_Service_ST3_210, service-interface-id=3194, service-interface-version={major-version=1, minor-version=0}
    someip event deployment SomeIp_TSSR_UI_Ctrl_Rq_ST3_210: event=TSSR_UI_Ctrl_Rq_Service_ST3_210/TSSR_UI_Ctrl_Rq_ST3, event-id=0, transport-protocol=UDP
    someip event group EG_3194_1_TSSR_UI_Ctrl: event-group-id=1, event=SomeIp_TSSR_UI_Ctrl_Rq_ST3_210
  signal based service interface deployment PSI_3194_TSSR_UI_Ctrl_Rq_Service_ST3_10_SignalBasedDeployment: service-interface=TSSR_UI_Ctrl_Rq_Service_ST3_210
  signal based service interface deployment PSI_3092_RollerBlindRear_UI_Ctrl_HU_Service_ST3_SignalBasedDeployment: service-interface=RollerBlindRear_UI_Ctrl_HU_Service_ST3_210
package /ServiceInterfaces/TransformationPropsSet
  transformation props set Transformer_Configuration_Package
    ap someip transformation props SOMEIP_8bit: alignment=8, byte-order=little-endian, is-dynamic-length-field-size=false, string-encoding=UTF-8
package /ServiceInterfaces/TransformationPropsToServiceInterfaceMappingSets
  transformation props to service interface element mapping set ServiceInterfaceTransformation
    6 x transformation props to service interface element mapping, all with transformation-props=SOMEIP_8bit:
      TSSR_UI_Ctrl_Rq_ST3_TransProps: event=TSSR_UI_Ctrl_Rq_Service_ST3/TSSR_UI_Ctrl_Rq_ST3
      VSS_TP_SecTickCount_Lvl1_ST3_TransProps: event=[VSS_Service_ST3/VSS_TP_Auth_ST3, VSS_Service_ST3/VSS_TP_RealTmOffset_ST3, VSS_TP_SecTickCount_Lvl1_ST3, VSS_Service_ST3/VSS_TP_SharedSecret_ST3, VSS_Service_ST3/VSS_TP_VIN_ST3]
      WprWashSw_Stat_ST3_TransProps: event=WprWashSw_Stat_ST3
      RollerBlindRear_UI_Ctrl_HU_Service_ST3_TransProps: event=RollerBlindRear_UI_Ctrl_HU_Service_ST3/RB_R_Rq_HU_ST3
      TSSR_UI_Ctrl_Rq_ST3_TransProps_210: event=TSSR_UI_Ctrl_Rq_Service_ST3_210/TSSR_UI_Ctrl_Rq_ST3
      RollerBlindRear_UI_Ctrl_HU_Service_ST3_TransProps_210: event=RollerBlindRear_UI_Ctrl_HU_Service_ST3_210/RB_R_Rq_HU_ST3
  transformation props to service interface element mapping set TransformationPropsToServiceInterfaceElementMappingSet
    5 x transformation props to service interface element mapping, all with transformation-props=SOMEIP_8bit:
      DI_OdoSpeedometer_ST3_TransProps: event=DI_OdoSpeedometer_ST3
      ECU_Stat_CIVIC_M_P_Service_ST3_TransProps: event=ECU_Stat_CIVIC_M_P_Service_ST3/ECU_Stat_CIVIC_M_P_Service_ST3
      Ign_Stat_ST3_TransProps: event=Ign_Stat_ST3
      PN14_Master_Service_ST3_TransProps: event=PN14_Master_Service_ST3/PN14_Master_Service_ST3
      PT4_PTCoor4_ST3_TransProps: event=PT4_PTCoor4_ST3
package /SoftwareDistribution/SoftwareCluster
  software cluster SoftwareClusterPlatform: contained-process=[DiagnosticManagerDeamon, InternalRouting_CIVIC_M_P_ST35_Process, SelfDiagnosticAgent_Process, amsr_ssadiagd, amsr_ssasecd], design=temporarySoftwareClusterDesignPer, diagnostic-extract=DcmContributionSet, vendor-id=4660, version=1.0.0.0000
    diagnostic-addresss:
      address-semantics=FUNCTIONAL-ADDRESS, diagnostic-address=2
      address-semantics=FUNCTIONAL-ADDRESS, diagnostic-address=3
      address-semantics=PHYSICAL-ADDRESS, diagnostic-address=1
package /SoftwareDistribution/SoftwareClusterDesign
  software cluster design temporarySoftwareClusterDesignPer: contained-process=[DiagnosticManagerDeamonDesign, InternalRouting_CIVIC_M_P_ST35_ProcessDesign, SelfDiagnosticAgent_ProcessDesign, amsr_ssadiagdDesign, amsr_ssasecdDesign], intended-target-machine=CIVIC_M_P_STAR_35_ExecutionContext
package /SoftwareDistribution/SoftwarePackage
  software package SoftwarePackagePlatform: software-cluster=SoftwareClusterPlatform
package /SoftwareTypes/Interfaces
  13 x sender receiver interface:
    ECU_Stat_CIVIC_M_P_Service_ST3
      data ECU_Stat_CIVIC_M_P_Service_ST3
    IG_DI_Odo_Pr5_ST3_dqmkbik4b90gceqe8t96kp3yd: category=FUNCTIONAL, invalidation-policy{data-element=DI_Odo_Pr5_ST3, handle-invalid=DONT-INVALIDATE}  # DriverInformation Odometer (degraded)
      data DI_Odo_Pr5_ST3: sw-calibration-access=READ-WRITE  # SHORT: DriverInformation Odometer LONG: DriverInformation Odometer (degraded)
    IG_Ign_Stat_Pr5_ST3_8qpxphk9meu9oryi6bfj0x04b: category=FUNCTIONAL, invalidation-policy{data-element=Ign_Stat_Pr5_ST3, handle-invalid=DONT-INVALIDATE}  # Ignition state (degraded)
      data Ign_Stat_Pr5_ST3: sw-calibration-access=READ-WRITE  # SHORT: Ignition state LONG: (degraded)
    IG_PT4_PTCoor4_Pr5_ST3_4jqmw0h0uwztlkj3fjsj9fpfe: category=FUNCTIONAL, invalidation-policy{data-element=PT4_PTCoor4_Pr5_ST3, handle-invalid=DONT-INVALIDATE}  # PT4_PTCoor4_Pr5_ST3 (degraded)
      data PT4_PTCoor4_Pr5_ST3: sw-calibration-access=READ-WRITE  # SHORT: PT4_PTCoor4_Pr5_ST3 LONG: PT4_PTCoor4_Pr5_ST3 (degraded)
    IG_TSSR_Sw_Stat_Pr5_ST3_2jon86tfhc3nwxtlfpjl4r9c2: category=FUNCTIONAL, invalidation-policy{data-element=TSSR_Sw_Stat_Pr5_ST3, handle-invalid=DONT-INVALIDATE}  # TSSR switch state (degraded)
      data TSSR_Sw_Stat_Pr5_ST3: sw-calibration-access=READ-WRITE  # SHORT: TSSR switch state LONG: TSSR switch state (degraded)
    IG_VSS_TP_Auth_ST3: category=FUNCTIONAL, invalidation-policy{data-element=IG_VSS_TP_Auth_ST3/VSS_TP_Auth_ST3, handle-invalid=DONT-INVALIDATE}  # Vehicle Security System Transport Protocol for authentication broadcast
      data VSS_TP_Auth_ST3: sw-calibration-access=READ-WRITE  # SHORT: Vehicle Security System Transport Protocol for authentication broadcast LONG: Vehicle Security System Transport Protocol for authentication broadcast
    IG_VSS_TP_RealTmOffset_ST3: category=FUNCTIONAL, invalidation-policy{data-element=IG_VSS_TP_RealTmOffset_ST3/VSS_TP_RealTmOffset_ST3, handle-invalid=DONT-INVALIDATE}  # Vehicle Security System Transport Protocol for real time offset broadcast
      data VSS_TP_RealTmOffset_ST3: sw-calibration-access=READ-WRITE  # SHORT: Vehicle Security System Transport Protocol for Vehicle Identification Number LONG: Vehicle Security System Transport Protocol for Vehicle Identification Number
    IG_VSS_TP_SecTickCount_ST3: category=FUNCTIONAL, invalidation-policy{data-element=VSS_TP_SecTickCount_ST3, handle-invalid=DONT-INVALIDATE}  # Vehicle Security System Transport Protocol for secure tick count
      data VSS_TP_SecTickCount_ST3: sw-calibration-access=READ-WRITE  # SHORT: Vehicle Security System Transport Protocol for secure tick count LONG: Vehicle Security System Transport Protocol for Vehicle Identification Number
    IG_VSS_TP_SharedSecret_ST3: category=FUNCTIONAL, invalidation-policy{data-element=IG_VSS_TP_SharedSecret_ST3/VSS_TP_SharedSecret_ST3, handle-invalid=DONT-INVALIDATE}  # Vehicle Security System Transport Protocol for shared secret broadcast
      data VSS_TP_SharedSecret_ST3: sw-calibration-access=READ-WRITE  # SHORT: Vehicle Security System Transport Protocol for Vehicle Identification Number LONG: Vehicle Security System Transport Protocol for Vehicle Identification Number
    IG_VSS_TP_VIN_ST3: category=FUNCTIONAL, invalidation-policy{data-element=IG_VSS_TP_VIN_ST3/VSS_TP_VIN_ST3, handle-invalid=DONT-INVALIDATE}  # Vehicle Security System Transport Protocol for Vehicle Identification Number
      data VSS_TP_VIN_ST3: sw-calibration-access=READ-WRITE  # SHORT: Vehicle Security System Transport Protocol for Vehicle Identification Number LONG: Vehicle Security System Transport Protocol for Vehicle Identification Number
    IG_WprWashSw_Stat_Pr5_ST3_9o61lt5oy0o224tt38pzu220c: category=FUNCTIONAL, invalidation-policy{data-element=WprWashSw_Stat_Pr5_ST3, handle-invalid=DONT-INVALIDATE}  # Wiper Wisher Switch State (degraded)
      data WprWashSw_Stat_Pr5_ST3: sw-calibration-access=READ-WRITE  # SHORT: Wiper Wisher Switch State LONG: Wiper Wisher Switch State (degraded)
    PN14_Master_Service_ST3
      data PN14_Master_Service_ST3
    IG_RollerBlindRear_UI_Ctrl_HU_Service_ST3: category=FUNCTIONAL, invalidation-policy{data-element=RollerBlinderEventName, handle-invalid=DONT-INVALIDATE}  # IG_TSSR_Sw_Stat_Pr5_ST3_2jon86tfhc3nwxtlfpjl4r9c2 | TSSR switch state (degraded)
      data RollerBlinderEventName: sw-calibration-access=READ-WRITE  # TSSR_Sw_Stat_Pr5_ST3 | SHORT: TSSR switch state LONG: TSSR switch state (degraded)
package /Topology/Clusters
  ethernet cluster MAIN_STAR_35
    ethernet physical channel ChannelCommunication10: category=WIRED
      pdu triggering DI_OdoSpeedometer_ST3_9dd1xsgdfjvdpzx8hpouqpux4: pdu=DI_OdoSpeedometer_ST3, to CIVIC_M_P_STAR_35_ExecutionContext
      pdu triggering Ign_Stat_ST3_8qmc9e64g3i0ppjmkg75hqh5c: pdu=Ign_Stat_ST3, to CIVIC_M_P_STAR_35_ExecutionContext
      pdu triggering PN14_Master_Stat1_ST3_cd8ybo6vwkbxr8qhj73guzpq5: pdu=PN14_Master_Stat1_ST3, to CIVIC_M_P_STAR_35_ExecutionContext
      pdu triggering PT4_PTCoor4_ST3_9avrr15qmp4tzvi9uyy38lsq3: pdu=PT4_PTCoor4_ST3, to CIVIC_M_P_STAR_35_ExecutionContext
      pdu triggering TSSR_UI_Ctrl_Rq_ST3_6l34silwnkmudjhvzfxd7dw5t: pdu=TSSR_UI_Ctrl_Rq_ST3, to CIVIC_M_P_STAR_35_ExecutionContext
      pdu triggering VSS_TP_Auth_ST3_9lhs80ginis5h5e8pbse0prde: pdu=VSS_TP_Auth_ST3, to CIVIC_M_P_STAR_35_ExecutionContext
      pdu triggering VSS_TP_RealTmOffset_ST3_spkj8fo2yxy4cmlkl5bftkno: pdu=VSS_TP_RealTmOffset_ST3, to CIVIC_M_P_STAR_35_ExecutionContext
      pdu triggering VSS_TP_SecTickCount_Lvl1_ST3_ic3ox80zmbo5njoxfrksuh0k: pdu=VSS_TP_SecTickCount_Lvl1_ST3, to CIVIC_M_P_STAR_35_ExecutionContext
      pdu triggering VSS_TP_SharedSecret_ST3_4elefqilhxcixkwvo92eg0oso: pdu=VSS_TP_SharedSecret_ST3, to CIVIC_M_P_STAR_35_ExecutionContext
      pdu triggering VSS_TP_VIN_ST3_6uqdcegerlaqr6iwjlv83z4r6: pdu=VSS_TP_VIN_ST3, to CIVIC_M_P_STAR_35_ExecutionContext
      pdu triggering WprWashSw_Stat_ST3_83wxevh8j70lsx68n13f0shsd: pdu=WprWashSw_Stat_ST3, to CIVIC_M_P_STAR_35_ExecutionContext
      pdu triggering RollerBlindRear_UI_Ctrl_HU_Service_ST3_6l34silwnkpotjhvzfxd7dw5t: pdu=RB_R_UI_Ctrl_HU_Stat_ST3, from CIVIC_M_P_STAR_35_ExecutionContext
      network endpoint NE_Multicast_Rx_fixed_239_10_0_2: network-endpoint-addresses=ipv-4-configuration={ipv-4-address=239.10.0.2, ipv-4-address-source=FIXED}
      network endpoint NE_fixed_10_10_1_90: network-endpoint-addresses=ipv-4-configuration={ipv-4-address=10.10.1.90, ipv-4-address-source=FIXED, network-mask=255.255.0.0, ttl=1}
      vlan MAIN_10: vlan-identifier=10
    ethernet physical channel ChannelCommunication127: category=WIRED
      pdu triggering ECU_Stat_CIVIC_M_P_ST3_2p45ivmv7xzbm4s3mga4mk24o: pdu=ECU_Stat_CIVIC_M_P_ST3, from CIVIC_M_P_STAR_35_ExecutionContext
      network endpoint NE_SomeIP_SD_MAIN_NW_CTRL_STAR_35: network-endpoint-addresses=ipv-4-configuration={ipv-4-address=239.127.0.2, ipv-4-address-source=FIXED, network-mask=255.255.0.0}
      network endpoint NE_fixed_10_127_1_90: network-endpoint-addresses=ipv-4-configuration={ipv-4-address=10.127.1.90, ipv-4-address-source=FIXED, network-mask=255.255.0.0, ttl=1}, priority=5
      vlan MAIN_NW_CTRL_STAR_35: vlan-identifier=127
    ethernet physical channel ChannelCommunication210: category=WIRED
      pdu triggering RollerBlindRear_UI_Ctrl_HU_Service_ST3_210hsilwnkpotjhvzfxd7dw5tl: pdu=RB_R_UI_Ctrl_HU_Stat_ST3, to CIVIC_M_P_STAR_35_ExecutionContext
      4 x network endpoint:
        NE_ANY: network-endpoint-addresses=ipv-4-configuration=ipv-4-address=0.0.0.0
        NE_fixed_10_210_220_2: network-endpoint-addresses=ipv-4-configuration={ipv-4-address=10.210.220.2, ipv-4-address-source=FIXED, network-mask=255.255.255.240}
        NE_Multicast_Rx_fixed_239_210_224_245: network-endpoint-addresses=ipv-4-configuration={ipv-4-address=239.210.224.245, ipv-4-address-source=FIXED}
        NE_Multicast_Rx_fixed_239_210_224_1: network-endpoint-addresses=ipv-4-configuration={ipv-4-address=239.210.224.1, ipv-4-address-source=FIXED}
      vlan MAIN_210: vlan-identifier=210
package /Topology/HardwareComponents
  machine design CIVIC_M_P_STAR_35_ExecutionContext: category=EXECUTION_CONTEXT
    ethernet communication connector CIVIC_M_P_START_35_MAIN10: category=WIRED, unicast-network-endpoint=NE_fixed_10_10_1_90
    ethernet communication connector CIVIC_M_P_START_35_MAIN127: category=WIRED, unicast-network-endpoint=NE_fixed_10_127_1_90
    ethernet communication connector CIVIC_M_P_START_35_MAIN210: category=WIRED, unicast-network-endpoint=NE_fixed_10_210_220_2
    service-discover-configs:
      multicast-sd-ip-address=NE_Multicast_Rx_fixed_239_10_0_2, someip-service-discovery-port=30490
      multicast-sd-ip-address=NE_SomeIP_SD_MAIN_NW_CTRL_STAR_35, someip-service-discovery-port=30490
      multicast-sd-ip-address=NE_Multicast_Rx_fixed_239_210_224_245, someip-service-discovery-port=30490
